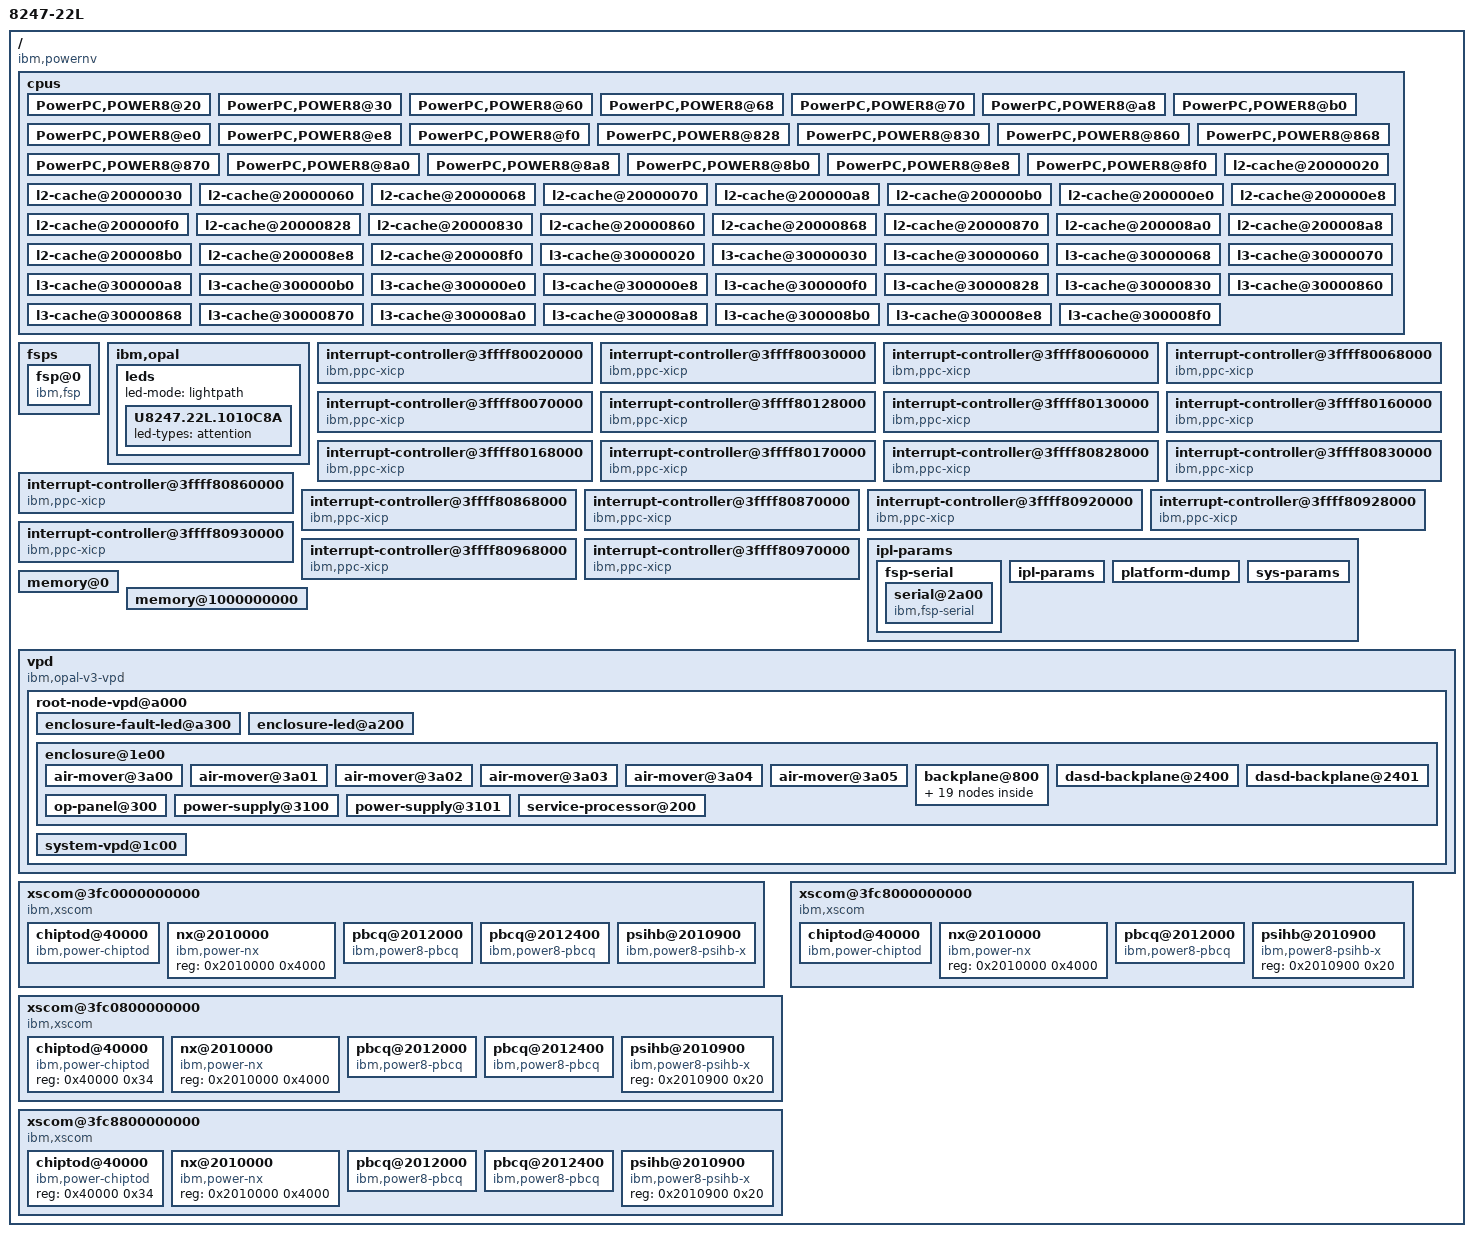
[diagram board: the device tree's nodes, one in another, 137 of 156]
/dts-v1/;

/memreserve/	0x0000001ffd586000 0x0000000000137000;
/memreserve/	0x0000001ffd6bd000 0x0000000000043000;
/memreserve/	0x0000001ffd700000 0x0000000000100000;

/ {
	phandle = <0x1>;
	#address-cells = <0x2>;
	#size-cells = <0x2>;
	lid-type = "phyp";
	compatible = "ibm,powernv", "ibm,firenze";
	nest-frequency = <0x0 0x77359400>;
	vendor = "IBM";
	ibm,io-base-loc-code = "U78CB.001.WZS00AL-P1";
	ibm,vpd-lx-info = <0x0 0x31000401 0x300042>;
	model = "8247-22L";
	system-id = "1010C8A";
	system-brand = "S0";
	model-name = "IBM Power System S822L";
	ibm,hbrt-mini-fdt = <0xcafebeef 0x1000 0xfad5bb>;
	reserved-ranges = <0x1f 0xfd700000 0x0 0x100000 0x1f 0xfd6bd000 0x0 0x43000 0x1f 0xfd586000 0x0 0x137000>;
	reserved-names = "ibm,hbrt-vpd-image", "ibm,hbrt-target-image", "ibm,hbrt-code-image";
	ibm,enabled-idle-states = "nap", "fast-sleep", "rvwinkle";

	cpus {
		phandle = <0x2a>;
		#address-cells = <0x1>;
		#size-cells = <0x0>;

		PowerPC,POWER8@20 {
			phandle = <0x2b>;
			device_type = "cpu";
			status = "okay";
			reg = <0x20>;
			cpu-version = <0x4b0201>;
			64-bit;
			32-64-bridge;
			graphics;
			general-purpose;
			ibm,processor-segment-sizes = <0x1c 0x28 0xffffffff 0xffffffff>;
			ibm,processor-page-sizes = <0xc 0x10 0x18 0x22>;
			ibm,segment-page-sizes = <0xc 0x0 0x3 0xc 0x0 0x10 0x7 0x18 0x38 0x10 0x110 0x2 0x10 0x1 0x18 0x8 0x18 0x100 0x1 0x18 0x0 0x22 0x120 0x1 0x22 0x3>;
			ibm,pa-features = [18 00 f6 3f c7 c0 80 d0 80 00 00 00 00 00 00 00 00 00 80 00 80 00 80 00 80 00];
			ibm,slb-size = <0x20>;
			ibm,vmx = <0x2>;
			ibm,dfp = <0x2>;
			ibm,purr = <0x1>;
			ibm,spurr = <0x1>;
			clock-frequency = <0xcc255a40>;
			ibm,extended-clock-frequency = <0x0 0xcc255a40>;
			timebase-frequency = <0x1e848000>;
			ibm,extended-timebase-frequency = <0x0 0x1e848000>;
			reservation-granule-size = <0x80>;
			d-tlb-size = <0x800>;
			i-tlb-size = <0x0>;
			tlb-size = <0x800>;
			d-tlb-sets = <0x4>;
			i-tlb-sets = <0x0>;
			tlb-sets = <0x4>;
			d-cache-block-size = <0x80>;
			i-cache-block-size = <0x80>;
			d-cache-size = <0x10000>;
			i-cache-size = <0x8000>;
			i-cache-sets = <0x4>;
			d-cache-sets = <0x8>;
			performance-monitor = <0x0 0x1>;
			l2-cache = <0x2c>;
			ibm,pir = <0x20>;
			ibm,chip-id = <0x0>;
			ibm,ppc-interrupt-server#s = <0x20 0x21 0x22 0x23 0x24 0x25 0x26 0x27>;
		};

		PowerPC,POWER8@30 {
			phandle = <0x2f>;
			device_type = "cpu";
			status = "okay";
			reg = <0x30>;
			cpu-version = <0x4b0201>;
			64-bit;
			32-64-bridge;
			graphics;
			general-purpose;
			ibm,processor-segment-sizes = <0x1c 0x28 0xffffffff 0xffffffff>;
			ibm,processor-page-sizes = <0xc 0x10 0x18 0x22>;
			ibm,segment-page-sizes = <0xc 0x0 0x3 0xc 0x0 0x10 0x7 0x18 0x38 0x10 0x110 0x2 0x10 0x1 0x18 0x8 0x18 0x100 0x1 0x18 0x0 0x22 0x120 0x1 0x22 0x3>;
			ibm,pa-features = [18 00 f6 3f c7 c0 80 d0 80 00 00 00 00 00 00 00 00 00 80 00 80 00 80 00 80 00];
			ibm,slb-size = <0x20>;
			ibm,vmx = <0x2>;
			ibm,dfp = <0x2>;
			ibm,purr = <0x1>;
			ibm,spurr = <0x1>;
			clock-frequency = <0xcc255a40>;
			ibm,extended-clock-frequency = <0x0 0xcc255a40>;
			timebase-frequency = <0x1e848000>;
			ibm,extended-timebase-frequency = <0x0 0x1e848000>;
			reservation-granule-size = <0x80>;
			d-tlb-size = <0x800>;
			i-tlb-size = <0x0>;
			tlb-size = <0x800>;
			d-tlb-sets = <0x4>;
			i-tlb-sets = <0x0>;
			tlb-sets = <0x4>;
			d-cache-block-size = <0x80>;
			i-cache-block-size = <0x80>;
			d-cache-size = <0x10000>;
			i-cache-size = <0x8000>;
			i-cache-sets = <0x4>;
			d-cache-sets = <0x8>;
			performance-monitor = <0x0 0x1>;
			l2-cache = <0x30>;
			ibm,pir = <0x30>;
			ibm,chip-id = <0x0>;
			ibm,ppc-interrupt-server#s = <0x30 0x31 0x32 0x33 0x34 0x35 0x36 0x37>;
		};

		PowerPC,POWER8@60 {
			phandle = <0x33>;
			device_type = "cpu";
			status = "okay";
			reg = <0x60>;
			cpu-version = <0x4b0201>;
			64-bit;
			32-64-bridge;
			graphics;
			general-purpose;
			ibm,processor-segment-sizes = <0x1c 0x28 0xffffffff 0xffffffff>;
			ibm,processor-page-sizes = <0xc 0x10 0x18 0x22>;
			ibm,segment-page-sizes = <0xc 0x0 0x3 0xc 0x0 0x10 0x7 0x18 0x38 0x10 0x110 0x2 0x10 0x1 0x18 0x8 0x18 0x100 0x1 0x18 0x0 0x22 0x120 0x1 0x22 0x3>;
			ibm,pa-features = [18 00 f6 3f c7 c0 80 d0 80 00 00 00 00 00 00 00 00 00 80 00 80 00 80 00 80 00];
			ibm,slb-size = <0x20>;
			ibm,vmx = <0x2>;
			ibm,dfp = <0x2>;
			ibm,purr = <0x1>;
			ibm,spurr = <0x1>;
			clock-frequency = <0xcc255a40>;
			ibm,extended-clock-frequency = <0x0 0xcc255a40>;
			timebase-frequency = <0x1e848000>;
			ibm,extended-timebase-frequency = <0x0 0x1e848000>;
			reservation-granule-size = <0x80>;
			d-tlb-size = <0x800>;
			i-tlb-size = <0x0>;
			tlb-size = <0x800>;
			d-tlb-sets = <0x4>;
			i-tlb-sets = <0x0>;
			tlb-sets = <0x4>;
			d-cache-block-size = <0x80>;
			i-cache-block-size = <0x80>;
			d-cache-size = <0x10000>;
			i-cache-size = <0x8000>;
			i-cache-sets = <0x4>;
			d-cache-sets = <0x8>;
			performance-monitor = <0x0 0x1>;
			l2-cache = <0x34>;
			ibm,pir = <0x60>;
			ibm,chip-id = <0x0>;
			ibm,ppc-interrupt-server#s = <0x60 0x61 0x62 0x63 0x64 0x65 0x66 0x67>;
		};

		PowerPC,POWER8@68 {
			phandle = <0x37>;
			device_type = "cpu";
			status = "okay";
			reg = <0x68>;
			cpu-version = <0x4b0201>;
			64-bit;
			32-64-bridge;
			graphics;
			general-purpose;
			ibm,processor-segment-sizes = <0x1c 0x28 0xffffffff 0xffffffff>;
			ibm,processor-page-sizes = <0xc 0x10 0x18 0x22>;
			ibm,segment-page-sizes = <0xc 0x0 0x3 0xc 0x0 0x10 0x7 0x18 0x38 0x10 0x110 0x2 0x10 0x1 0x18 0x8 0x18 0x100 0x1 0x18 0x0 0x22 0x120 0x1 0x22 0x3>;
			ibm,pa-features = [18 00 f6 3f c7 c0 80 d0 80 00 00 00 00 00 00 00 00 00 80 00 80 00 80 00 80 00];
			ibm,slb-size = <0x20>;
			ibm,vmx = <0x2>;
			ibm,dfp = <0x2>;
			ibm,purr = <0x1>;
			ibm,spurr = <0x1>;
			clock-frequency = <0xcc255a40>;
			ibm,extended-clock-frequency = <0x0 0xcc255a40>;
			timebase-frequency = <0x1e848000>;
			ibm,extended-timebase-frequency = <0x0 0x1e848000>;
			reservation-granule-size = <0x80>;
			d-tlb-size = <0x800>;
			i-tlb-size = <0x0>;
			tlb-size = <0x800>;
			d-tlb-sets = <0x4>;
			i-tlb-sets = <0x0>;
			tlb-sets = <0x4>;
			d-cache-block-size = <0x80>;
			i-cache-block-size = <0x80>;
			d-cache-size = <0x10000>;
			i-cache-size = <0x8000>;
			i-cache-sets = <0x4>;
			d-cache-sets = <0x8>;
			performance-monitor = <0x0 0x1>;
			l2-cache = <0x38>;
			ibm,pir = <0x68>;
			ibm,chip-id = <0x0>;
			ibm,ppc-interrupt-server#s = <0x68 0x69 0x6a 0x6b 0x6c 0x6d 0x6e 0x6f>;
		};

		PowerPC,POWER8@70 {
			phandle = <0x3b>;
			device_type = "cpu";
			status = "okay";
			reg = <0x70>;
			cpu-version = <0x4b0201>;
			64-bit;
			32-64-bridge;
			graphics;
			general-purpose;
			ibm,processor-segment-sizes = <0x1c 0x28 0xffffffff 0xffffffff>;
			ibm,processor-page-sizes = <0xc 0x10 0x18 0x22>;
			ibm,segment-page-sizes = <0xc 0x0 0x3 0xc 0x0 0x10 0x7 0x18 0x38 0x10 0x110 0x2 0x10 0x1 0x18 0x8 0x18 0x100 0x1 0x18 0x0 0x22 0x120 0x1 0x22 0x3>;
			ibm,pa-features = [18 00 f6 3f c7 c0 80 d0 80 00 00 00 00 00 00 00 00 00 80 00 80 00 80 00 80 00];
			ibm,slb-size = <0x20>;
			ibm,vmx = <0x2>;
			ibm,dfp = <0x2>;
			ibm,purr = <0x1>;
			ibm,spurr = <0x1>;
			clock-frequency = <0xcc255a40>;
			ibm,extended-clock-frequency = <0x0 0xcc255a40>;
			timebase-frequency = <0x1e848000>;
			ibm,extended-timebase-frequency = <0x0 0x1e848000>;
			reservation-granule-size = <0x80>;
			d-tlb-size = <0x800>;
			i-tlb-size = <0x0>;
			tlb-size = <0x800>;
			d-tlb-sets = <0x4>;
			i-tlb-sets = <0x0>;
			tlb-sets = <0x4>;
			d-cache-block-size = <0x80>;
			i-cache-block-size = <0x80>;
			d-cache-size = <0x10000>;
			i-cache-size = <0x8000>;
			i-cache-sets = <0x4>;
			d-cache-sets = <0x8>;
			performance-monitor = <0x0 0x1>;
			l2-cache = <0x3c>;
			ibm,pir = <0x70>;
			ibm,chip-id = <0x0>;
			ibm,ppc-interrupt-server#s = <0x70 0x71 0x72 0x73 0x74 0x75 0x76 0x77>;
		};

		PowerPC,POWER8@a8 {
			phandle = <0x3f>;
			device_type = "cpu";
			status = "okay";
			reg = <0xa8>;
			cpu-version = <0x4b0201>;
			64-bit;
			32-64-bridge;
			graphics;
			general-purpose;
			ibm,processor-segment-sizes = <0x1c 0x28 0xffffffff 0xffffffff>;
			ibm,processor-page-sizes = <0xc 0x10 0x18 0x22>;
			ibm,segment-page-sizes = <0xc 0x0 0x3 0xc 0x0 0x10 0x7 0x18 0x38 0x10 0x110 0x2 0x10 0x1 0x18 0x8 0x18 0x100 0x1 0x18 0x0 0x22 0x120 0x1 0x22 0x3>;
			ibm,pa-features = [18 00 f6 3f c7 c0 80 d0 80 00 00 00 00 00 00 00 00 00 80 00 80 00 80 00 80 00];
			ibm,slb-size = <0x20>;
			ibm,vmx = <0x2>;
			ibm,dfp = <0x2>;
			ibm,purr = <0x1>;
			ibm,spurr = <0x1>;
			clock-frequency = <0xcc255a40>;
			ibm,extended-clock-frequency = <0x0 0xcc255a40>;
			timebase-frequency = <0x1e848000>;
			ibm,extended-timebase-frequency = <0x0 0x1e848000>;
			reservation-granule-size = <0x80>;
			d-tlb-size = <0x800>;
			i-tlb-size = <0x0>;
			tlb-size = <0x800>;
			d-tlb-sets = <0x4>;
			i-tlb-sets = <0x0>;
			tlb-sets = <0x4>;
			d-cache-block-size = <0x80>;
			i-cache-block-size = <0x80>;
			d-cache-size = <0x10000>;
			i-cache-size = <0x8000>;
			i-cache-sets = <0x4>;
			d-cache-sets = <0x8>;
			performance-monitor = <0x0 0x1>;
			l2-cache = <0x40>;
			ibm,pir = <0xa8>;
			ibm,chip-id = <0x1>;
			ibm,ppc-interrupt-server#s = <0xa8 0xa9 0xaa 0xab 0xac 0xad 0xae 0xaf>;
		};

		PowerPC,POWER8@b0 {
			phandle = <0x43>;
			device_type = "cpu";
			status = "okay";
			reg = <0xb0>;
			cpu-version = <0x4b0201>;
			64-bit;
			32-64-bridge;
			graphics;
			general-purpose;
			ibm,processor-segment-sizes = <0x1c 0x28 0xffffffff 0xffffffff>;
			ibm,processor-page-sizes = <0xc 0x10 0x18 0x22>;
			ibm,segment-page-sizes = <0xc 0x0 0x3 0xc 0x0 0x10 0x7 0x18 0x38 0x10 0x110 0x2 0x10 0x1 0x18 0x8 0x18 0x100 0x1 0x18 0x0 0x22 0x120 0x1 0x22 0x3>;
			ibm,pa-features = [18 00 f6 3f c7 c0 80 d0 80 00 00 00 00 00 00 00 00 00 80 00 80 00 80 00 80 00];
			ibm,slb-size = <0x20>;
			ibm,vmx = <0x2>;
			ibm,dfp = <0x2>;
			ibm,purr = <0x1>;
			ibm,spurr = <0x1>;
			clock-frequency = <0xcc255a40>;
			ibm,extended-clock-frequency = <0x0 0xcc255a40>;
			timebase-frequency = <0x1e848000>;
			ibm,extended-timebase-frequency = <0x0 0x1e848000>;
			reservation-granule-size = <0x80>;
			d-tlb-size = <0x800>;
			i-tlb-size = <0x0>;
			tlb-size = <0x800>;
			d-tlb-sets = <0x4>;
			i-tlb-sets = <0x0>;
			tlb-sets = <0x4>;
			d-cache-block-size = <0x80>;
			i-cache-block-size = <0x80>;
			d-cache-size = <0x10000>;
			i-cache-size = <0x8000>;
			i-cache-sets = <0x4>;
			d-cache-sets = <0x8>;
			performance-monitor = <0x0 0x1>;
			l2-cache = <0x44>;
			ibm,pir = <0xb0>;
			ibm,chip-id = <0x1>;
			ibm,ppc-interrupt-server#s = <0xb0 0xb1 0xb2 0xb3 0xb4 0xb5 0xb6 0xb7>;
		};

		PowerPC,POWER8@e0 {
			phandle = <0x47>;
			device_type = "cpu";
			status = "okay";
			reg = <0xe0>;
			cpu-version = <0x4b0201>;
			64-bit;
			32-64-bridge;
			graphics;
			general-purpose;
			ibm,processor-segment-sizes = <0x1c 0x28 0xffffffff 0xffffffff>;
			ibm,processor-page-sizes = <0xc 0x10 0x18 0x22>;
			ibm,segment-page-sizes = <0xc 0x0 0x3 0xc 0x0 0x10 0x7 0x18 0x38 0x10 0x110 0x2 0x10 0x1 0x18 0x8 0x18 0x100 0x1 0x18 0x0 0x22 0x120 0x1 0x22 0x3>;
			ibm,pa-features = [18 00 f6 3f c7 c0 80 d0 80 00 00 00 00 00 00 00 00 00 80 00 80 00 80 00 80 00];
			ibm,slb-size = <0x20>;
			ibm,vmx = <0x2>;
			ibm,dfp = <0x2>;
			ibm,purr = <0x1>;
			ibm,spurr = <0x1>;
			clock-frequency = <0xcc255a40>;
			ibm,extended-clock-frequency = <0x0 0xcc255a40>;
			timebase-frequency = <0x1e848000>;
			ibm,extended-timebase-frequency = <0x0 0x1e848000>;
			reservation-granule-size = <0x80>;
			d-tlb-size = <0x800>;
			i-tlb-size = <0x0>;
			tlb-size = <0x800>;
			d-tlb-sets = <0x4>;
			i-tlb-sets = <0x0>;
			tlb-sets = <0x4>;
			d-cache-block-size = <0x80>;
			i-cache-block-size = <0x80>;
			d-cache-size = <0x10000>;
			i-cache-size = <0x8000>;
			i-cache-sets = <0x4>;
			d-cache-sets = <0x8>;
			performance-monitor = <0x0 0x1>;
			l2-cache = <0x48>;
			ibm,pir = <0xe0>;
			ibm,chip-id = <0x1>;
			ibm,ppc-interrupt-server#s = <0xe0 0xe1 0xe2 0xe3 0xe4 0xe5 0xe6 0xe7>;
		};

		PowerPC,POWER8@e8 {
			phandle = <0x4b>;
			device_type = "cpu";
			status = "okay";
			reg = <0xe8>;
			cpu-version = <0x4b0201>;
			64-bit;
			32-64-bridge;
			graphics;
			general-purpose;
			ibm,processor-segment-sizes = <0x1c 0x28 0xffffffff 0xffffffff>;
			ibm,processor-page-sizes = <0xc 0x10 0x18 0x22>;
			ibm,segment-page-sizes = <0xc 0x0 0x3 0xc 0x0 0x10 0x7 0x18 0x38 0x10 0x110 0x2 0x10 0x1 0x18 0x8 0x18 0x100 0x1 0x18 0x0 0x22 0x120 0x1 0x22 0x3>;
			ibm,pa-features = [18 00 f6 3f c7 c0 80 d0 80 00 00 00 00 00 00 00 00 00 80 00 80 00 80 00 80 00];
			ibm,slb-size = <0x20>;
			ibm,vmx = <0x2>;
			ibm,dfp = <0x2>;
			ibm,purr = <0x1>;
			ibm,spurr = <0x1>;
			clock-frequency = <0xcc255a40>;
			ibm,extended-clock-frequency = <0x0 0xcc255a40>;
			timebase-frequency = <0x1e848000>;
			ibm,extended-timebase-frequency = <0x0 0x1e848000>;
			reservation-granule-size = <0x80>;
			d-tlb-size = <0x800>;
			i-tlb-size = <0x0>;
			tlb-size = <0x800>;
			d-tlb-sets = <0x4>;
			i-tlb-sets = <0x0>;
			tlb-sets = <0x4>;
			d-cache-block-size = <0x80>;
			i-cache-block-size = <0x80>;
			d-cache-size = <0x10000>;
			i-cache-size = <0x8000>;
			i-cache-sets = <0x4>;
			d-cache-sets = <0x8>;
			performance-monitor = <0x0 0x1>;
			l2-cache = <0x4c>;
			ibm,pir = <0xe8>;
			ibm,chip-id = <0x1>;
			ibm,ppc-interrupt-server#s = <0xe8 0xe9 0xea 0xeb 0xec 0xed 0xee 0xef>;
		};

		PowerPC,POWER8@f0 {
			phandle = <0x4f>;
			device_type = "cpu";
			status = "okay";
			reg = <0xf0>;
			cpu-version = <0x4b0201>;
			64-bit;
			32-64-bridge;
			graphics;
			general-purpose;
			ibm,processor-segment-sizes = <0x1c 0x28 0xffffffff 0xffffffff>;
			ibm,processor-page-sizes = <0xc 0x10 0x18 0x22>;
			ibm,segment-page-sizes = <0xc 0x0 0x3 0xc 0x0 0x10 0x7 0x18 0x38 0x10 0x110 0x2 0x10 0x1 0x18 0x8 0x18 0x100 0x1 0x18 0x0 0x22 0x120 0x1 0x22 0x3>;
			ibm,pa-features = [18 00 f6 3f c7 c0 80 d0 80 00 00 00 00 00 00 00 00 00 80 00 80 00 80 00 80 00];
			ibm,slb-size = <0x20>;
			ibm,vmx = <0x2>;
			ibm,dfp = <0x2>;
			ibm,purr = <0x1>;
			ibm,spurr = <0x1>;
			clock-frequency = <0xcc255a40>;
			ibm,extended-clock-frequency = <0x0 0xcc255a40>;
			timebase-frequency = <0x1e848000>;
			ibm,extended-timebase-frequency = <0x0 0x1e848000>;
			reservation-granule-size = <0x80>;
			d-tlb-size = <0x800>;
			i-tlb-size = <0x0>;
			tlb-size = <0x800>;
			d-tlb-sets = <0x4>;
			i-tlb-sets = <0x0>;
			tlb-sets = <0x4>;
			d-cache-block-size = <0x80>;
			i-cache-block-size = <0x80>;
			d-cache-size = <0x10000>;
			i-cache-size = <0x8000>;
			i-cache-sets = <0x4>;
			d-cache-sets = <0x8>;
			performance-monitor = <0x0 0x1>;
			l2-cache = <0x50>;
			ibm,pir = <0xf0>;
			ibm,chip-id = <0x1>;
			ibm,ppc-interrupt-server#s = <0xf0 0xf1 0xf2 0xf3 0xf4 0xf5 0xf6 0xf7>;
		};

		PowerPC,POWER8@828 {
			phandle = <0x53>;
			device_type = "cpu";
			status = "okay";
			reg = <0x828>;
			cpu-version = <0x4b0201>;
			64-bit;
			32-64-bridge;
			graphics;
			general-purpose;
			ibm,processor-segment-sizes = <0x1c 0x28 0xffffffff 0xffffffff>;
			ibm,processor-page-sizes = <0xc 0x10 0x18 0x22>;
			ibm,segment-page-sizes = <0xc 0x0 0x3 0xc 0x0 0x10 0x7 0x18 0x38 0x10 0x110 0x2 0x10 0x1 0x18 0x8 0x18 0x100 0x1 0x18 0x0 0x22 0x120 0x1 0x22 0x3>;
			ibm,pa-features = [18 00 f6 3f c7 c0 80 d0 80 00 00 00 00 00 00 00 00 00 80 00 80 00 80 00 80 00];
			ibm,slb-size = <0x20>;
			ibm,vmx = <0x2>;
			ibm,dfp = <0x2>;
			ibm,purr = <0x1>;
			ibm,spurr = <0x1>;
			clock-frequency = <0xcc255a40>;
			ibm,extended-clock-frequency = <0x0 0xcc255a40>;
			timebase-frequency = <0x1e848000>;
			ibm,extended-timebase-frequency = <0x0 0x1e848000>;
			reservation-granule-size = <0x80>;
			d-tlb-size = <0x800>;
			i-tlb-size = <0x0>;
			tlb-size = <0x800>;
			d-tlb-sets = <0x4>;
			i-tlb-sets = <0x0>;
			tlb-sets = <0x4>;
			d-cache-block-size = <0x80>;
			i-cache-block-size = <0x80>;
			d-cache-size = <0x10000>;
			i-cache-size = <0x8000>;
			i-cache-sets = <0x4>;
			d-cache-sets = <0x8>;
			performance-monitor = <0x0 0x1>;
			l2-cache = <0x54>;
			ibm,pir = <0x828>;
			ibm,chip-id = <0x10>;
			ibm,ppc-interrupt-server#s = <0x828 0x829 0x82a 0x82b 0x82c 0x82d 0x82e 0x82f>;
		};

		PowerPC,POWER8@830 {
			phandle = <0x57>;
			device_type = "cpu";
			status = "okay";
			reg = <0x830>;
			cpu-version = <0x4b0201>;
			64-bit;
			32-64-bridge;
			graphics;
			general-purpose;
			ibm,processor-segment-sizes = <0x1c 0x28 0xffffffff 0xffffffff>;
			ibm,processor-page-sizes = <0xc 0x10 0x18 0x22>;
			ibm,segment-page-sizes = <0xc 0x0 0x3 0xc 0x0 0x10 0x7 0x18 0x38 0x10 0x110 0x2 0x10 0x1 0x18 0x8 0x18 0x100 0x1 0x18 0x0 0x22 0x120 0x1 0x22 0x3>;
			ibm,pa-features = [18 00 f6 3f c7 c0 80 d0 80 00 00 00 00 00 00 00 00 00 80 00 80 00 80 00 80 00];
			ibm,slb-size = <0x20>;
			ibm,vmx = <0x2>;
			ibm,dfp = <0x2>;
			ibm,purr = <0x1>;
			ibm,spurr = <0x1>;
			clock-frequency = <0xcc255a40>;
			ibm,extended-clock-frequency = <0x0 0xcc255a40>;
			timebase-frequency = <0x1e848000>;
			ibm,extended-timebase-frequency = <0x0 0x1e848000>;
			reservation-granule-size = <0x80>;
			d-tlb-size = <0x800>;
			i-tlb-size = <0x0>;
			tlb-size = <0x800>;
			d-tlb-sets = <0x4>;
			i-tlb-sets = <0x0>;
			tlb-sets = <0x4>;
			d-cache-block-size = <0x80>;
			i-cache-block-size = <0x80>;
			d-cache-size = <0x10000>;
			i-cache-size = <0x8000>;
			i-cache-sets = <0x4>;
			d-cache-sets = <0x8>;
			performance-monitor = <0x0 0x1>;
			l2-cache = <0x58>;
			ibm,pir = <0x830>;
			ibm,chip-id = <0x10>;
			ibm,ppc-interrupt-server#s = <0x830 0x831 0x832 0x833 0x834 0x835 0x836 0x837>;
		};

		PowerPC,POWER8@860 {
			phandle = <0x5b>;
			device_type = "cpu";
			status = "okay";
			reg = <0x860>;
			cpu-version = <0x4b0201>;
			64-bit;
			32-64-bridge;
			graphics;
			general-purpose;
			ibm,processor-segment-sizes = <0x1c 0x28 0xffffffff 0xffffffff>;
			ibm,processor-page-sizes = <0xc 0x10 0x18 0x22>;
			ibm,segment-page-sizes = <0xc 0x0 0x3 0xc 0x0 0x10 0x7 0x18 0x38 0x10 0x110 0x2 0x10 0x1 0x18 0x8 0x18 0x100 0x1 0x18 0x0 0x22 0x120 0x1 0x22 0x3>;
			ibm,pa-features = [18 00 f6 3f c7 c0 80 d0 80 00 00 00 00 00 00 00 00 00 80 00 80 00 80 00 80 00];
			ibm,slb-size = <0x20>;
			ibm,vmx = <0x2>;
			ibm,dfp = <0x2>;
			ibm,purr = <0x1>;
			ibm,spurr = <0x1>;
			clock-frequency = <0xcc255a40>;
			ibm,extended-clock-frequency = <0x0 0xcc255a40>;
			timebase-frequency = <0x1e848000>;
			ibm,extended-timebase-frequency = <0x0 0x1e848000>;
			reservation-granule-size = <0x80>;
			d-tlb-size = <0x800>;
			i-tlb-size = <0x0>;
			tlb-size = <0x800>;
			d-tlb-sets = <0x4>;
			i-tlb-sets = <0x0>;
			tlb-sets = <0x4>;
			d-cache-block-size = <0x80>;
			i-cache-block-size = <0x80>;
			d-cache-size = <0x10000>;
			i-cache-size = <0x8000>;
			i-cache-sets = <0x4>;
			d-cache-sets = <0x8>;
			performance-monitor = <0x0 0x1>;
			l2-cache = <0x5c>;
			ibm,pir = <0x860>;
			ibm,chip-id = <0x10>;
			ibm,ppc-interrupt-server#s = <0x860 0x861 0x862 0x863 0x864 0x865 0x866 0x867>;
		};

		PowerPC,POWER8@868 {
			phandle = <0x5f>;
			device_type = "cpu";
			status = "okay";
			reg = <0x868>;
			cpu-version = <0x4b0201>;
			64-bit;
			32-64-bridge;
			graphics;
			general-purpose;
			ibm,processor-segment-sizes = <0x1c 0x28 0xffffffff 0xffffffff>;
			ibm,processor-page-sizes = <0xc 0x10 0x18 0x22>;
			ibm,segment-page-sizes = <0xc 0x0 0x3 0xc 0x0 0x10 0x7 0x18 0x38 0x10 0x110 0x2 0x10 0x1 0x18 0x8 0x18 0x100 0x1 0x18 0x0 0x22 0x120 0x1 0x22 0x3>;
			ibm,pa-features = [18 00 f6 3f c7 c0 80 d0 80 00 00 00 00 00 00 00 00 00 80 00 80 00 80 00 80 00];
			ibm,slb-size = <0x20>;
			ibm,vmx = <0x2>;
			ibm,dfp = <0x2>;
			ibm,purr = <0x1>;
			ibm,spurr = <0x1>;
			clock-frequency = <0xcc255a40>;
			ibm,extended-clock-frequency = <0x0 0xcc255a40>;
			timebase-frequency = <0x1e848000>;
			ibm,extended-timebase-frequency = <0x0 0x1e848000>;
			reservation-granule-size = <0x80>;
			d-tlb-size = <0x800>;
			i-tlb-size = <0x0>;
			tlb-size = <0x800>;
			d-tlb-sets = <0x4>;
			i-tlb-sets = <0x0>;
			tlb-sets = <0x4>;
			d-cache-block-size = <0x80>;
			i-cache-block-size = <0x80>;
			d-cache-size = <0x10000>;
			i-cache-size = <0x8000>;
			i-cache-sets = <0x4>;
			d-cache-sets = <0x8>;
			performance-monitor = <0x0 0x1>;
			l2-cache = <0x60>;
			ibm,pir = <0x868>;
			ibm,chip-id = <0x10>;
			ibm,ppc-interrupt-server#s = <0x868 0x869 0x86a 0x86b 0x86c 0x86d 0x86e 0x86f>;
		};

		PowerPC,POWER8@870 {
			phandle = <0x63>;
			device_type = "cpu";
			status = "okay";
			reg = <0x870>;
			cpu-version = <0x4b0201>;
			64-bit;
			32-64-bridge;
			graphics;
			general-purpose;
			ibm,processor-segment-sizes = <0x1c 0x28 0xffffffff 0xffffffff>;
			ibm,processor-page-sizes = <0xc 0x10 0x18 0x22>;
			ibm,segment-page-sizes = <0xc 0x0 0x3 0xc 0x0 0x10 0x7 0x18 0x38 0x10 0x110 0x2 0x10 0x1 0x18 0x8 0x18 0x100 0x1 0x18 0x0 0x22 0x120 0x1 0x22 0x3>;
			ibm,pa-features = [18 00 f6 3f c7 c0 80 d0 80 00 00 00 00 00 00 00 00 00 80 00 80 00 80 00 80 00];
			ibm,slb-size = <0x20>;
			ibm,vmx = <0x2>;
			ibm,dfp = <0x2>;
			ibm,purr = <0x1>;
			ibm,spurr = <0x1>;
			clock-frequency = <0xcc255a40>;
			ibm,extended-clock-frequency = <0x0 0xcc255a40>;
			timebase-frequency = <0x1e848000>;
			ibm,extended-timebase-frequency = <0x0 0x1e848000>;
			reservation-granule-size = <0x80>;
			d-tlb-size = <0x800>;
			i-tlb-size = <0x0>;
			tlb-size = <0x800>;
			d-tlb-sets = <0x4>;
			i-tlb-sets = <0x0>;
			tlb-sets = <0x4>;
			d-cache-block-size = <0x80>;
			i-cache-block-size = <0x80>;
			d-cache-size = <0x10000>;
			i-cache-size = <0x8000>;
			i-cache-sets = <0x4>;
			d-cache-sets = <0x8>;
			performance-monitor = <0x0 0x1>;
			l2-cache = <0x64>;
			ibm,pir = <0x870>;
			ibm,chip-id = <0x10>;
			ibm,ppc-interrupt-server#s = <0x870 0x871 0x872 0x873 0x874 0x875 0x876 0x877>;
		};

		PowerPC,POWER8@8a0 {
			phandle = <0x67>;
			device_type = "cpu";
			status = "okay";
			reg = <0x8a0>;
			cpu-version = <0x4b0201>;
			64-bit;
			32-64-bridge;
			graphics;
			general-purpose;
			ibm,processor-segment-sizes = <0x1c 0x28 0xffffffff 0xffffffff>;
			ibm,processor-page-sizes = <0xc 0x10 0x18 0x22>;
			ibm,segment-page-sizes = <0xc 0x0 0x3 0xc 0x0 0x10 0x7 0x18 0x38 0x10 0x110 0x2 0x10 0x1 0x18 0x8 0x18 0x100 0x1 0x18 0x0 0x22 0x120 0x1 0x22 0x3>;
			ibm,pa-features = [18 00 f6 3f c7 c0 80 d0 80 00 00 00 00 00 00 00 00 00 80 00 80 00 80 00 80 00];
			ibm,slb-size = <0x20>;
			ibm,vmx = <0x2>;
			ibm,dfp = <0x2>;
			ibm,purr = <0x1>;
			ibm,spurr = <0x1>;
			clock-frequency = <0xcc255a40>;
			ibm,extended-clock-frequency = <0x0 0xcc255a40>;
			timebase-frequency = <0x1e848000>;
			ibm,extended-timebase-frequency = <0x0 0x1e848000>;
			reservation-granule-size = <0x80>;
			d-tlb-size = <0x800>;
			i-tlb-size = <0x0>;
			tlb-size = <0x800>;
			d-tlb-sets = <0x4>;
			i-tlb-sets = <0x0>;
			tlb-sets = <0x4>;
			d-cache-block-size = <0x80>;
			i-cache-block-size = <0x80>;
			d-cache-size = <0x10000>;
			i-cache-size = <0x8000>;
			i-cache-sets = <0x4>;
			d-cache-sets = <0x8>;
			performance-monitor = <0x0 0x1>;
			l2-cache = <0x68>;
			ibm,pir = <0x8a0>;
			ibm,chip-id = <0x11>;
			ibm,ppc-interrupt-server#s = <0x8a0 0x8a1 0x8a2 0x8a3 0x8a4 0x8a5 0x8a6 0x8a7>;
		};

		PowerPC,POWER8@8a8 {
			phandle = <0x6b>;
			device_type = "cpu";
			status = "okay";
			reg = <0x8a8>;
			cpu-version = <0x4b0201>;
			64-bit;
			32-64-bridge;
			graphics;
			general-purpose;
			ibm,processor-segment-sizes = <0x1c 0x28 0xffffffff 0xffffffff>;
			ibm,processor-page-sizes = <0xc 0x10 0x18 0x22>;
			ibm,segment-page-sizes = <0xc 0x0 0x3 0xc 0x0 0x10 0x7 0x18 0x38 0x10 0x110 0x2 0x10 0x1 0x18 0x8 0x18 0x100 0x1 0x18 0x0 0x22 0x120 0x1 0x22 0x3>;
			ibm,pa-features = [18 00 f6 3f c7 c0 80 d0 80 00 00 00 00 00 00 00 00 00 80 00 80 00 80 00 80 00];
			ibm,slb-size = <0x20>;
			ibm,vmx = <0x2>;
			ibm,dfp = <0x2>;
			ibm,purr = <0x1>;
			ibm,spurr = <0x1>;
			clock-frequency = <0xcc255a40>;
			ibm,extended-clock-frequency = <0x0 0xcc255a40>;
			timebase-frequency = <0x1e848000>;
			ibm,extended-timebase-frequency = <0x0 0x1e848000>;
			reservation-granule-size = <0x80>;
			d-tlb-size = <0x800>;
			i-tlb-size = <0x0>;
			tlb-size = <0x800>;
			d-tlb-sets = <0x4>;
			i-tlb-sets = <0x0>;
			tlb-sets = <0x4>;
			d-cache-block-size = <0x80>;
			i-cache-block-size = <0x80>;
			d-cache-size = <0x10000>;
			i-cache-size = <0x8000>;
			i-cache-sets = <0x4>;
			d-cache-sets = <0x8>;
			performance-monitor = <0x0 0x1>;
			l2-cache = <0x6c>;
			ibm,pir = <0x8a8>;
			ibm,chip-id = <0x11>;
			ibm,ppc-interrupt-server#s = <0x8a8 0x8a9 0x8aa 0x8ab 0x8ac 0x8ad 0x8ae 0x8af>;
		};

		PowerPC,POWER8@8b0 {
			phandle = <0x6f>;
			device_type = "cpu";
			status = "okay";
			reg = <0x8b0>;
			cpu-version = <0x4b0201>;
			64-bit;
			32-64-bridge;
			graphics;
			general-purpose;
			ibm,processor-segment-sizes = <0x1c 0x28 0xffffffff 0xffffffff>;
			ibm,processor-page-sizes = <0xc 0x10 0x18 0x22>;
			ibm,segment-page-sizes = <0xc 0x0 0x3 0xc 0x0 0x10 0x7 0x18 0x38 0x10 0x110 0x2 0x10 0x1 0x18 0x8 0x18 0x100 0x1 0x18 0x0 0x22 0x120 0x1 0x22 0x3>;
			ibm,pa-features = [18 00 f6 3f c7 c0 80 d0 80 00 00 00 00 00 00 00 00 00 80 00 80 00 80 00 80 00];
			ibm,slb-size = <0x20>;
			ibm,vmx = <0x2>;
			ibm,dfp = <0x2>;
			ibm,purr = <0x1>;
			ibm,spurr = <0x1>;
			clock-frequency = <0xcc255a40>;
			ibm,extended-clock-frequency = <0x0 0xcc255a40>;
			timebase-frequency = <0x1e848000>;
			ibm,extended-timebase-frequency = <0x0 0x1e848000>;
			reservation-granule-size = <0x80>;
			d-tlb-size = <0x800>;
			i-tlb-size = <0x0>;
			tlb-size = <0x800>;
			d-tlb-sets = <0x4>;
			i-tlb-sets = <0x0>;
			tlb-sets = <0x4>;
			d-cache-block-size = <0x80>;
			i-cache-block-size = <0x80>;
			d-cache-size = <0x10000>;
			i-cache-size = <0x8000>;
			i-cache-sets = <0x4>;
			d-cache-sets = <0x8>;
			performance-monitor = <0x0 0x1>;
			l2-cache = <0x70>;
			ibm,pir = <0x8b0>;
			ibm,chip-id = <0x11>;
			ibm,ppc-interrupt-server#s = <0x8b0 0x8b1 0x8b2 0x8b3 0x8b4 0x8b5 0x8b6 0x8b7>;
		};

		PowerPC,POWER8@8e8 {
			phandle = <0x73>;
			device_type = "cpu";
			status = "okay";
			reg = <0x8e8>;
			cpu-version = <0x4b0201>;
			64-bit;
			32-64-bridge;
			graphics;
			general-purpose;
			ibm,processor-segment-sizes = <0x1c 0x28 0xffffffff 0xffffffff>;
			ibm,processor-page-sizes = <0xc 0x10 0x18 0x22>;
			ibm,segment-page-sizes = <0xc 0x0 0x3 0xc 0x0 0x10 0x7 0x18 0x38 0x10 0x110 0x2 0x10 0x1 0x18 0x8 0x18 0x100 0x1 0x18 0x0 0x22 0x120 0x1 0x22 0x3>;
			ibm,pa-features = [18 00 f6 3f c7 c0 80 d0 80 00 00 00 00 00 00 00 00 00 80 00 80 00 80 00 80 00];
			ibm,slb-size = <0x20>;
			ibm,vmx = <0x2>;
			ibm,dfp = <0x2>;
			ibm,purr = <0x1>;
			ibm,spurr = <0x1>;
			clock-frequency = <0xcc255a40>;
			ibm,extended-clock-frequency = <0x0 0xcc255a40>;
			timebase-frequency = <0x1e848000>;
			ibm,extended-timebase-frequency = <0x0 0x1e848000>;
			reservation-granule-size = <0x80>;
			d-tlb-size = <0x800>;
			i-tlb-size = <0x0>;
			tlb-size = <0x800>;
			d-tlb-sets = <0x4>;
			i-tlb-sets = <0x0>;
			tlb-sets = <0x4>;
			d-cache-block-size = <0x80>;
			i-cache-block-size = <0x80>;
			d-cache-size = <0x10000>;
			i-cache-size = <0x8000>;
			i-cache-sets = <0x4>;
			d-cache-sets = <0x8>;
			performance-monitor = <0x0 0x1>;
			l2-cache = <0x74>;
			ibm,pir = <0x8e8>;
			ibm,chip-id = <0x11>;
			ibm,ppc-interrupt-server#s = <0x8e8 0x8e9 0x8ea 0x8eb 0x8ec 0x8ed 0x8ee 0x8ef>;
		};

		PowerPC,POWER8@8f0 {
			phandle = <0x77>;
			device_type = "cpu";
			status = "okay";
			reg = <0x8f0>;
			cpu-version = <0x4b0201>;
			64-bit;
			32-64-bridge;
			graphics;
			general-purpose;
			ibm,processor-segment-sizes = <0x1c 0x28 0xffffffff 0xffffffff>;
			ibm,processor-page-sizes = <0xc 0x10 0x18 0x22>;
			ibm,segment-page-sizes = <0xc 0x0 0x3 0xc 0x0 0x10 0x7 0x18 0x38 0x10 0x110 0x2 0x10 0x1 0x18 0x8 0x18 0x100 0x1 0x18 0x0 0x22 0x120 0x1 0x22 0x3>;
			ibm,pa-features = [18 00 f6 3f c7 c0 80 d0 80 00 00 00 00 00 00 00 00 00 80 00 80 00 80 00 80 00];
			ibm,slb-size = <0x20>;
			ibm,vmx = <0x2>;
			ibm,dfp = <0x2>;
			ibm,purr = <0x1>;
			ibm,spurr = <0x1>;
			clock-frequency = <0xcc255a40>;
			ibm,extended-clock-frequency = <0x0 0xcc255a40>;
			timebase-frequency = <0x1e848000>;
			ibm,extended-timebase-frequency = <0x0 0x1e848000>;
			reservation-granule-size = <0x80>;
			d-tlb-size = <0x800>;
			i-tlb-size = <0x0>;
			tlb-size = <0x800>;
			d-tlb-sets = <0x4>;
			i-tlb-sets = <0x0>;
			tlb-sets = <0x4>;
			d-cache-block-size = <0x80>;
			i-cache-block-size = <0x80>;
			d-cache-size = <0x10000>;
			i-cache-size = <0x8000>;
			i-cache-sets = <0x4>;
			d-cache-sets = <0x8>;
			performance-monitor = <0x0 0x1>;
			l2-cache = <0x78>;
			ibm,pir = <0x8f0>;
			ibm,chip-id = <0x11>;
			ibm,ppc-interrupt-server#s = <0x8f0 0x8f1 0x8f2 0x8f3 0x8f4 0x8f5 0x8f6 0x8f7>;
		};

		l2-cache@20000020 {
			phandle = <0x2c>;
			device_type = "cache";
			reg = <0x20000020>;
			status = "okay";
			cache-unified;
			d-cache-sets = <0x8>;
			i-cache-sets = <0x8>;
			d-cache-size = <0x80000>;
			i-cache-size = <0x80000>;
			l2-cache = <0x2d>;
		};

		l2-cache@20000030 {
			phandle = <0x30>;
			device_type = "cache";
			reg = <0x20000030>;
			status = "okay";
			cache-unified;
			d-cache-sets = <0x8>;
			i-cache-sets = <0x8>;
			d-cache-size = <0x80000>;
			i-cache-size = <0x80000>;
			l2-cache = <0x31>;
		};

		l2-cache@20000060 {
			phandle = <0x34>;
			device_type = "cache";
			reg = <0x20000060>;
			status = "okay";
			cache-unified;
			d-cache-sets = <0x8>;
			i-cache-sets = <0x8>;
			d-cache-size = <0x80000>;
			i-cache-size = <0x80000>;
			l2-cache = <0x35>;
		};

		l2-cache@20000068 {
			phandle = <0x38>;
			device_type = "cache";
			reg = <0x20000068>;
			status = "okay";
			cache-unified;
			d-cache-sets = <0x8>;
			i-cache-sets = <0x8>;
			d-cache-size = <0x80000>;
			i-cache-size = <0x80000>;
			l2-cache = <0x39>;
		};

		l2-cache@20000070 {
			phandle = <0x3c>;
			device_type = "cache";
			reg = <0x20000070>;
			status = "okay";
			cache-unified;
			d-cache-sets = <0x8>;
			i-cache-sets = <0x8>;
			d-cache-size = <0x80000>;
			i-cache-size = <0x80000>;
			l2-cache = <0x3d>;
		};

		l2-cache@200000a8 {
			phandle = <0x40>;
			device_type = "cache";
			reg = <0x200000a8>;
			status = "okay";
			cache-unified;
			d-cache-sets = <0x8>;
			i-cache-sets = <0x8>;
			d-cache-size = <0x80000>;
			i-cache-size = <0x80000>;
			l2-cache = <0x41>;
		};

		l2-cache@200000b0 {
			phandle = <0x44>;
			device_type = "cache";
			reg = <0x200000b0>;
			status = "okay";
			cache-unified;
			d-cache-sets = <0x8>;
			i-cache-sets = <0x8>;
			d-cache-size = <0x80000>;
			i-cache-size = <0x80000>;
			l2-cache = <0x45>;
		};

		l2-cache@200000e0 {
			phandle = <0x48>;
			device_type = "cache";
			reg = <0x200000e0>;
			status = "okay";
			cache-unified;
			d-cache-sets = <0x8>;
			i-cache-sets = <0x8>;
			d-cache-size = <0x80000>;
			i-cache-size = <0x80000>;
			l2-cache = <0x49>;
		};

		l2-cache@200000e8 {
			phandle = <0x4c>;
			device_type = "cache";
			reg = <0x200000e8>;
			status = "okay";
			cache-unified;
			d-cache-sets = <0x8>;
			i-cache-sets = <0x8>;
			d-cache-size = <0x80000>;
			i-cache-size = <0x80000>;
			l2-cache = <0x4d>;
		};

		l2-cache@200000f0 {
			phandle = <0x50>;
			device_type = "cache";
			reg = <0x200000f0>;
			status = "okay";
			cache-unified;
			d-cache-sets = <0x8>;
			i-cache-sets = <0x8>;
			d-cache-size = <0x80000>;
			i-cache-size = <0x80000>;
			l2-cache = <0x51>;
		};

		l2-cache@20000828 {
			phandle = <0x54>;
			device_type = "cache";
			reg = <0x20000828>;
			status = "okay";
			cache-unified;
			d-cache-sets = <0x8>;
			i-cache-sets = <0x8>;
			d-cache-size = <0x80000>;
			i-cache-size = <0x80000>;
			l2-cache = <0x55>;
		};

		l2-cache@20000830 {
			phandle = <0x58>;
			device_type = "cache";
			reg = <0x20000830>;
			status = "okay";
			cache-unified;
			d-cache-sets = <0x8>;
			i-cache-sets = <0x8>;
			d-cache-size = <0x80000>;
			i-cache-size = <0x80000>;
			l2-cache = <0x59>;
		};

		l2-cache@20000860 {
			phandle = <0x5c>;
			device_type = "cache";
			reg = <0x20000860>;
			status = "okay";
			cache-unified;
			d-cache-sets = <0x8>;
			i-cache-sets = <0x8>;
			d-cache-size = <0x80000>;
			i-cache-size = <0x80000>;
			l2-cache = <0x5d>;
		};

		l2-cache@20000868 {
			phandle = <0x60>;
			device_type = "cache";
			reg = <0x20000868>;
			status = "okay";
			cache-unified;
			d-cache-sets = <0x8>;
			i-cache-sets = <0x8>;
			d-cache-size = <0x80000>;
			i-cache-size = <0x80000>;
			l2-cache = <0x61>;
		};

		l2-cache@20000870 {
			phandle = <0x64>;
			device_type = "cache";
			reg = <0x20000870>;
			status = "okay";
			cache-unified;
			d-cache-sets = <0x8>;
			i-cache-sets = <0x8>;
			d-cache-size = <0x80000>;
			i-cache-size = <0x80000>;
			l2-cache = <0x65>;
		};

		l2-cache@200008a0 {
			phandle = <0x68>;
			device_type = "cache";
			reg = <0x200008a0>;
			status = "okay";
			cache-unified;
			d-cache-sets = <0x8>;
			i-cache-sets = <0x8>;
			d-cache-size = <0x80000>;
			i-cache-size = <0x80000>;
			l2-cache = <0x69>;
		};

		l2-cache@200008a8 {
			phandle = <0x6c>;
			device_type = "cache";
			reg = <0x200008a8>;
			status = "okay";
			cache-unified;
			d-cache-sets = <0x8>;
			i-cache-sets = <0x8>;
			d-cache-size = <0x80000>;
			i-cache-size = <0x80000>;
			l2-cache = <0x6d>;
		};

		l2-cache@200008b0 {
			phandle = <0x70>;
			device_type = "cache";
			reg = <0x200008b0>;
			status = "okay";
			cache-unified;
			d-cache-sets = <0x8>;
			i-cache-sets = <0x8>;
			d-cache-size = <0x80000>;
			i-cache-size = <0x80000>;
			l2-cache = <0x71>;
		};

		l2-cache@200008e8 {
			phandle = <0x74>;
			device_type = "cache";
			reg = <0x200008e8>;
			status = "okay";
			cache-unified;
			d-cache-sets = <0x8>;
			i-cache-sets = <0x8>;
			d-cache-size = <0x80000>;
			i-cache-size = <0x80000>;
			l2-cache = <0x75>;
		};

		l2-cache@200008f0 {
			phandle = <0x78>;
			device_type = "cache";
			reg = <0x200008f0>;
			status = "okay";
			cache-unified;
			d-cache-sets = <0x8>;
			i-cache-sets = <0x8>;
			d-cache-size = <0x80000>;
			i-cache-size = <0x80000>;
			l2-cache = <0x79>;
		};

		l3-cache@30000020 {
			phandle = <0x2d>;
			device_type = "cache";
			reg = <0x30000020>;
			status = "okay";
			cache-unified;
			d-cache-sets = <0x8>;
			i-cache-sets = <0x8>;
			d-cache-size = <0x800000>;
			i-cache-size = <0x800000>;
		};

		l3-cache@30000030 {
			phandle = <0x31>;
			device_type = "cache";
			reg = <0x30000030>;
			status = "okay";
			cache-unified;
			d-cache-sets = <0x8>;
			i-cache-sets = <0x8>;
			d-cache-size = <0x800000>;
			i-cache-size = <0x800000>;
		};

		l3-cache@30000060 {
			phandle = <0x35>;
			device_type = "cache";
			reg = <0x30000060>;
			status = "okay";
			cache-unified;
			d-cache-sets = <0x8>;
			i-cache-sets = <0x8>;
			d-cache-size = <0x800000>;
			i-cache-size = <0x800000>;
		};

		l3-cache@30000068 {
			phandle = <0x39>;
			device_type = "cache";
			reg = <0x30000068>;
			status = "okay";
			cache-unified;
			d-cache-sets = <0x8>;
			i-cache-sets = <0x8>;
			d-cache-size = <0x800000>;
			i-cache-size = <0x800000>;
		};

		l3-cache@30000070 {
			phandle = <0x3d>;
			device_type = "cache";
			reg = <0x30000070>;
			status = "okay";
			cache-unified;
			d-cache-sets = <0x8>;
			i-cache-sets = <0x8>;
			d-cache-size = <0x800000>;
			i-cache-size = <0x800000>;
		};

		l3-cache@300000a8 {
			phandle = <0x41>;
			device_type = "cache";
			reg = <0x300000a8>;
			status = "okay";
			cache-unified;
			d-cache-sets = <0x8>;
			i-cache-sets = <0x8>;
			d-cache-size = <0x800000>;
			i-cache-size = <0x800000>;
		};

		l3-cache@300000b0 {
			phandle = <0x45>;
			device_type = "cache";
			reg = <0x300000b0>;
			status = "okay";
			cache-unified;
			d-cache-sets = <0x8>;
			i-cache-sets = <0x8>;
			d-cache-size = <0x800000>;
			i-cache-size = <0x800000>;
		};

		l3-cache@300000e0 {
			phandle = <0x49>;
			device_type = "cache";
			reg = <0x300000e0>;
			status = "okay";
			cache-unified;
			d-cache-sets = <0x8>;
			i-cache-sets = <0x8>;
			d-cache-size = <0x800000>;
			i-cache-size = <0x800000>;
		};

		l3-cache@300000e8 {
			phandle = <0x4d>;
			device_type = "cache";
			reg = <0x300000e8>;
			status = "okay";
			cache-unified;
			d-cache-sets = <0x8>;
			i-cache-sets = <0x8>;
			d-cache-size = <0x800000>;
			i-cache-size = <0x800000>;
		};

		l3-cache@300000f0 {
			phandle = <0x51>;
			device_type = "cache";
			reg = <0x300000f0>;
			status = "okay";
			cache-unified;
			d-cache-sets = <0x8>;
			i-cache-sets = <0x8>;
			d-cache-size = <0x800000>;
			i-cache-size = <0x800000>;
		};

		l3-cache@30000828 {
			phandle = <0x55>;
			device_type = "cache";
			reg = <0x30000828>;
			status = "okay";
			cache-unified;
			d-cache-sets = <0x8>;
			i-cache-sets = <0x8>;
			d-cache-size = <0x800000>;
			i-cache-size = <0x800000>;
		};

		l3-cache@30000830 {
			phandle = <0x59>;
			device_type = "cache";
			reg = <0x30000830>;
			status = "okay";
			cache-unified;
			d-cache-sets = <0x8>;
			i-cache-sets = <0x8>;
			d-cache-size = <0x800000>;
			i-cache-size = <0x800000>;
		};

		l3-cache@30000860 {
			phandle = <0x5d>;
			device_type = "cache";
			reg = <0x30000860>;
			status = "okay";
			cache-unified;
			d-cache-sets = <0x8>;
			i-cache-sets = <0x8>;
			d-cache-size = <0x800000>;
			i-cache-size = <0x800000>;
		};

		l3-cache@30000868 {
			phandle = <0x61>;
			device_type = "cache";
			reg = <0x30000868>;
			status = "okay";
			cache-unified;
			d-cache-sets = <0x8>;
			i-cache-sets = <0x8>;
			d-cache-size = <0x800000>;
			i-cache-size = <0x800000>;
		};

		l3-cache@30000870 {
			phandle = <0x65>;
			device_type = "cache";
			reg = <0x30000870>;
			status = "okay";
			cache-unified;
			d-cache-sets = <0x8>;
			i-cache-sets = <0x8>;
			d-cache-size = <0x800000>;
			i-cache-size = <0x800000>;
		};

		l3-cache@300008a0 {
			phandle = <0x69>;
			device_type = "cache";
			reg = <0x300008a0>;
			status = "okay";
			cache-unified;
			d-cache-sets = <0x8>;
			i-cache-sets = <0x8>;
			d-cache-size = <0x800000>;
			i-cache-size = <0x800000>;
		};

		l3-cache@300008a8 {
			phandle = <0x6d>;
			device_type = "cache";
			reg = <0x300008a8>;
			status = "okay";
			cache-unified;
			d-cache-sets = <0x8>;
			i-cache-sets = <0x8>;
			d-cache-size = <0x800000>;
			i-cache-size = <0x800000>;
		};

		l3-cache@300008b0 {
			phandle = <0x71>;
			device_type = "cache";
			reg = <0x300008b0>;
			status = "okay";
			cache-unified;
			d-cache-sets = <0x8>;
			i-cache-sets = <0x8>;
			d-cache-size = <0x800000>;
			i-cache-size = <0x800000>;
		};

		l3-cache@300008e8 {
			phandle = <0x75>;
			device_type = "cache";
			reg = <0x300008e8>;
			status = "okay";
			cache-unified;
			d-cache-sets = <0x8>;
			i-cache-sets = <0x8>;
			d-cache-size = <0x800000>;
			i-cache-size = <0x800000>;
		};

		l3-cache@300008f0 {
			phandle = <0x79>;
			device_type = "cache";
			reg = <0x300008f0>;
			status = "okay";
			cache-unified;
			d-cache-sets = <0x8>;
			i-cache-sets = <0x8>;
			d-cache-size = <0x800000>;
			i-cache-size = <0x800000>;
		};
	};

	fsps {
		phandle = <0x8b>;
		#address-cells = <0x1>;
		#size-cells = <0x0>;

		fsp@0 {
			phandle = <0x8c>;
			reg = <0x0>;
			compatible = "ibm,fsp", "ibm,fsp2";
			reg-offset = <0xb0011000>;
			hw-version = <0x2>;
			sw-version = <0x1>;
			primary;
			ibm,psi-links = <0x0 0x10>;
		};
	};

	ibm,opal {
		phandle = <0x28>;

		leds {
			phandle = <0x29>;
			led-mode = "lightpath";

			U8247.22L.1010C8A {
				phandle = <0x9d>;
				led-types = "attention";
			};
		};
	};

	interrupt-controller@3ffff80020000 {
		phandle = <0x2e>;
		compatible = "ibm,ppc-xicp", "IBM,power8-icp";
		ibm,interrupt-server-ranges = <0x20 0x8>;
		interrupt-controller;
		reg = <0x3ffff 0x80020000 0x0 0x1000 0x3ffff 0x80021000 0x0 0x1000 0x3ffff 0x80022000 0x0 0x1000 0x3ffff 0x80023000 0x0 0x1000 0x3ffff 0x80024000 0x0 0x1000 0x3ffff 0x80025000 0x0 0x1000 0x3ffff 0x80026000 0x0 0x1000 0x3ffff 0x80027000 0x0 0x1000>;
		#address-cells = <0x0>;
		device_type = "PowerPC-External-Interrupt-Presentation";
	};

	interrupt-controller@3ffff80030000 {
		phandle = <0x32>;
		compatible = "ibm,ppc-xicp", "IBM,power8-icp";
		ibm,interrupt-server-ranges = <0x30 0x8>;
		interrupt-controller;
		reg = <0x3ffff 0x80030000 0x0 0x1000 0x3ffff 0x80031000 0x0 0x1000 0x3ffff 0x80032000 0x0 0x1000 0x3ffff 0x80033000 0x0 0x1000 0x3ffff 0x80034000 0x0 0x1000 0x3ffff 0x80035000 0x0 0x1000 0x3ffff 0x80036000 0x0 0x1000 0x3ffff 0x80037000 0x0 0x1000>;
		#address-cells = <0x0>;
		device_type = "PowerPC-External-Interrupt-Presentation";
	};

	interrupt-controller@3ffff80060000 {
		phandle = <0x36>;
		compatible = "ibm,ppc-xicp", "IBM,power8-icp";
		ibm,interrupt-server-ranges = <0x60 0x8>;
		interrupt-controller;
		reg = <0x3ffff 0x80060000 0x0 0x1000 0x3ffff 0x80061000 0x0 0x1000 0x3ffff 0x80062000 0x0 0x1000 0x3ffff 0x80063000 0x0 0x1000 0x3ffff 0x80064000 0x0 0x1000 0x3ffff 0x80065000 0x0 0x1000 0x3ffff 0x80066000 0x0 0x1000 0x3ffff 0x80067000 0x0 0x1000>;
		#address-cells = <0x0>;
		device_type = "PowerPC-External-Interrupt-Presentation";
	};

	interrupt-controller@3ffff80068000 {
		phandle = <0x3a>;
		compatible = "ibm,ppc-xicp", "IBM,power8-icp";
		ibm,interrupt-server-ranges = <0x68 0x8>;
		interrupt-controller;
		reg = <0x3ffff 0x80068000 0x0 0x1000 0x3ffff 0x80069000 0x0 0x1000 0x3ffff 0x8006a000 0x0 0x1000 0x3ffff 0x8006b000 0x0 0x1000 0x3ffff 0x8006c000 0x0 0x1000 0x3ffff 0x8006d000 0x0 0x1000 0x3ffff 0x8006e000 0x0 0x1000 0x3ffff 0x8006f000 0x0 0x1000>;
		#address-cells = <0x0>;
		device_type = "PowerPC-External-Interrupt-Presentation";
	};

	interrupt-controller@3ffff80070000 {
		phandle = <0x3e>;
		compatible = "ibm,ppc-xicp", "IBM,power8-icp";
		ibm,interrupt-server-ranges = <0x70 0x8>;
		interrupt-controller;
		reg = <0x3ffff 0x80070000 0x0 0x1000 0x3ffff 0x80071000 0x0 0x1000 0x3ffff 0x80072000 0x0 0x1000 0x3ffff 0x80073000 0x0 0x1000 0x3ffff 0x80074000 0x0 0x1000 0x3ffff 0x80075000 0x0 0x1000 0x3ffff 0x80076000 0x0 0x1000 0x3ffff 0x80077000 0x0 0x1000>;
		#address-cells = <0x0>;
		device_type = "PowerPC-External-Interrupt-Presentation";
	};

	interrupt-controller@3ffff80128000 {
		phandle = <0x42>;
		compatible = "ibm,ppc-xicp", "IBM,power8-icp";
		ibm,interrupt-server-ranges = <0xa8 0x8>;
		interrupt-controller;
		reg = <0x3ffff 0x80128000 0x0 0x1000 0x3ffff 0x80129000 0x0 0x1000 0x3ffff 0x8012a000 0x0 0x1000 0x3ffff 0x8012b000 0x0 0x1000 0x3ffff 0x8012c000 0x0 0x1000 0x3ffff 0x8012d000 0x0 0x1000 0x3ffff 0x8012e000 0x0 0x1000 0x3ffff 0x8012f000 0x0 0x1000>;
		#address-cells = <0x0>;
		device_type = "PowerPC-External-Interrupt-Presentation";
	};

	interrupt-controller@3ffff80130000 {
		phandle = <0x46>;
		compatible = "ibm,ppc-xicp", "IBM,power8-icp";
		ibm,interrupt-server-ranges = <0xb0 0x8>;
		interrupt-controller;
		reg = <0x3ffff 0x80130000 0x0 0x1000 0x3ffff 0x80131000 0x0 0x1000 0x3ffff 0x80132000 0x0 0x1000 0x3ffff 0x80133000 0x0 0x1000 0x3ffff 0x80134000 0x0 0x1000 0x3ffff 0x80135000 0x0 0x1000 0x3ffff 0x80136000 0x0 0x1000 0x3ffff 0x80137000 0x0 0x1000>;
		#address-cells = <0x0>;
		device_type = "PowerPC-External-Interrupt-Presentation";
	};

	interrupt-controller@3ffff80160000 {
		phandle = <0x4a>;
		compatible = "ibm,ppc-xicp", "IBM,power8-icp";
		ibm,interrupt-server-ranges = <0xe0 0x8>;
		interrupt-controller;
		reg = <0x3ffff 0x80160000 0x0 0x1000 0x3ffff 0x80161000 0x0 0x1000 0x3ffff 0x80162000 0x0 0x1000 0x3ffff 0x80163000 0x0 0x1000 0x3ffff 0x80164000 0x0 0x1000 0x3ffff 0x80165000 0x0 0x1000 0x3ffff 0x80166000 0x0 0x1000 0x3ffff 0x80167000 0x0 0x1000>;
		#address-cells = <0x0>;
		device_type = "PowerPC-External-Interrupt-Presentation";
	};

	interrupt-controller@3ffff80168000 {
		phandle = <0x4e>;
		compatible = "ibm,ppc-xicp", "IBM,power8-icp";
		ibm,interrupt-server-ranges = <0xe8 0x8>;
		interrupt-controller;
		reg = <0x3ffff 0x80168000 0x0 0x1000 0x3ffff 0x80169000 0x0 0x1000 0x3ffff 0x8016a000 0x0 0x1000 0x3ffff 0x8016b000 0x0 0x1000 0x3ffff 0x8016c000 0x0 0x1000 0x3ffff 0x8016d000 0x0 0x1000 0x3ffff 0x8016e000 0x0 0x1000 0x3ffff 0x8016f000 0x0 0x1000>;
		#address-cells = <0x0>;
		device_type = "PowerPC-External-Interrupt-Presentation";
	};

	interrupt-controller@3ffff80170000 {
		phandle = <0x52>;
		compatible = "ibm,ppc-xicp", "IBM,power8-icp";
		ibm,interrupt-server-ranges = <0xf0 0x8>;
		interrupt-controller;
		reg = <0x3ffff 0x80170000 0x0 0x1000 0x3ffff 0x80171000 0x0 0x1000 0x3ffff 0x80172000 0x0 0x1000 0x3ffff 0x80173000 0x0 0x1000 0x3ffff 0x80174000 0x0 0x1000 0x3ffff 0x80175000 0x0 0x1000 0x3ffff 0x80176000 0x0 0x1000 0x3ffff 0x80177000 0x0 0x1000>;
		#address-cells = <0x0>;
		device_type = "PowerPC-External-Interrupt-Presentation";
	};

	interrupt-controller@3ffff80828000 {
		phandle = <0x56>;
		compatible = "ibm,ppc-xicp", "IBM,power8-icp";
		ibm,interrupt-server-ranges = <0x828 0x8>;
		interrupt-controller;
		reg = <0x3ffff 0x80828000 0x0 0x1000 0x3ffff 0x80829000 0x0 0x1000 0x3ffff 0x8082a000 0x0 0x1000 0x3ffff 0x8082b000 0x0 0x1000 0x3ffff 0x8082c000 0x0 0x1000 0x3ffff 0x8082d000 0x0 0x1000 0x3ffff 0x8082e000 0x0 0x1000 0x3ffff 0x8082f000 0x0 0x1000>;
		#address-cells = <0x0>;
		device_type = "PowerPC-External-Interrupt-Presentation";
	};

	interrupt-controller@3ffff80830000 {
		phandle = <0x5a>;
		compatible = "ibm,ppc-xicp", "IBM,power8-icp";
		ibm,interrupt-server-ranges = <0x830 0x8>;
		interrupt-controller;
		reg = <0x3ffff 0x80830000 0x0 0x1000 0x3ffff 0x80831000 0x0 0x1000 0x3ffff 0x80832000 0x0 0x1000 0x3ffff 0x80833000 0x0 0x1000 0x3ffff 0x80834000 0x0 0x1000 0x3ffff 0x80835000 0x0 0x1000 0x3ffff 0x80836000 0x0 0x1000 0x3ffff 0x80837000 0x0 0x1000>;
		#address-cells = <0x0>;
		device_type = "PowerPC-External-Interrupt-Presentation";
	};

	interrupt-controller@3ffff80860000 {
		phandle = <0x5e>;
		compatible = "ibm,ppc-xicp", "IBM,power8-icp";
		ibm,interrupt-server-ranges = <0x860 0x8>;
		interrupt-controller;
		reg = <0x3ffff 0x80860000 0x0 0x1000 0x3ffff 0x80861000 0x0 0x1000 0x3ffff 0x80862000 0x0 0x1000 0x3ffff 0x80863000 0x0 0x1000 0x3ffff 0x80864000 0x0 0x1000 0x3ffff 0x80865000 0x0 0x1000 0x3ffff 0x80866000 0x0 0x1000 0x3ffff 0x80867000 0x0 0x1000>;
		#address-cells = <0x0>;
		device_type = "PowerPC-External-Interrupt-Presentation";
	};

	interrupt-controller@3ffff80868000 {
		phandle = <0x62>;
		compatible = "ibm,ppc-xicp", "IBM,power8-icp";
		ibm,interrupt-server-ranges = <0x868 0x8>;
		interrupt-controller;
		reg = <0x3ffff 0x80868000 0x0 0x1000 0x3ffff 0x80869000 0x0 0x1000 0x3ffff 0x8086a000 0x0 0x1000 0x3ffff 0x8086b000 0x0 0x1000 0x3ffff 0x8086c000 0x0 0x1000 0x3ffff 0x8086d000 0x0 0x1000 0x3ffff 0x8086e000 0x0 0x1000 0x3ffff 0x8086f000 0x0 0x1000>;
		#address-cells = <0x0>;
		device_type = "PowerPC-External-Interrupt-Presentation";
	};

	interrupt-controller@3ffff80870000 {
		phandle = <0x66>;
		compatible = "ibm,ppc-xicp", "IBM,power8-icp";
		ibm,interrupt-server-ranges = <0x870 0x8>;
		interrupt-controller;
		reg = <0x3ffff 0x80870000 0x0 0x1000 0x3ffff 0x80871000 0x0 0x1000 0x3ffff 0x80872000 0x0 0x1000 0x3ffff 0x80873000 0x0 0x1000 0x3ffff 0x80874000 0x0 0x1000 0x3ffff 0x80875000 0x0 0x1000 0x3ffff 0x80876000 0x0 0x1000 0x3ffff 0x80877000 0x0 0x1000>;
		#address-cells = <0x0>;
		device_type = "PowerPC-External-Interrupt-Presentation";
	};

	interrupt-controller@3ffff80920000 {
		phandle = <0x6a>;
		compatible = "ibm,ppc-xicp", "IBM,power8-icp";
		ibm,interrupt-server-ranges = <0x8a0 0x8>;
		interrupt-controller;
		reg = <0x3ffff 0x80920000 0x0 0x1000 0x3ffff 0x80921000 0x0 0x1000 0x3ffff 0x80922000 0x0 0x1000 0x3ffff 0x80923000 0x0 0x1000 0x3ffff 0x80924000 0x0 0x1000 0x3ffff 0x80925000 0x0 0x1000 0x3ffff 0x80926000 0x0 0x1000 0x3ffff 0x80927000 0x0 0x1000>;
		#address-cells = <0x0>;
		device_type = "PowerPC-External-Interrupt-Presentation";
	};

	interrupt-controller@3ffff80928000 {
		phandle = <0x6e>;
		compatible = "ibm,ppc-xicp", "IBM,power8-icp";
		ibm,interrupt-server-ranges = <0x8a8 0x8>;
		interrupt-controller;
		reg = <0x3ffff 0x80928000 0x0 0x1000 0x3ffff 0x80929000 0x0 0x1000 0x3ffff 0x8092a000 0x0 0x1000 0x3ffff 0x8092b000 0x0 0x1000 0x3ffff 0x8092c000 0x0 0x1000 0x3ffff 0x8092d000 0x0 0x1000 0x3ffff 0x8092e000 0x0 0x1000 0x3ffff 0x8092f000 0x0 0x1000>;
		#address-cells = <0x0>;
		device_type = "PowerPC-External-Interrupt-Presentation";
	};

	interrupt-controller@3ffff80930000 {
		phandle = <0x72>;
		compatible = "ibm,ppc-xicp", "IBM,power8-icp";
		ibm,interrupt-server-ranges = <0x8b0 0x8>;
		interrupt-controller;
		reg = <0x3ffff 0x80930000 0x0 0x1000 0x3ffff 0x80931000 0x0 0x1000 0x3ffff 0x80932000 0x0 0x1000 0x3ffff 0x80933000 0x0 0x1000 0x3ffff 0x80934000 0x0 0x1000 0x3ffff 0x80935000 0x0 0x1000 0x3ffff 0x80936000 0x0 0x1000 0x3ffff 0x80937000 0x0 0x1000>;
		#address-cells = <0x0>;
		device_type = "PowerPC-External-Interrupt-Presentation";
	};

	interrupt-controller@3ffff80968000 {
		phandle = <0x76>;
		compatible = "ibm,ppc-xicp", "IBM,power8-icp";
		ibm,interrupt-server-ranges = <0x8e8 0x8>;
		interrupt-controller;
		reg = <0x3ffff 0x80968000 0x0 0x1000 0x3ffff 0x80969000 0x0 0x1000 0x3ffff 0x8096a000 0x0 0x1000 0x3ffff 0x8096b000 0x0 0x1000 0x3ffff 0x8096c000 0x0 0x1000 0x3ffff 0x8096d000 0x0 0x1000 0x3ffff 0x8096e000 0x0 0x1000 0x3ffff 0x8096f000 0x0 0x1000>;
		#address-cells = <0x0>;
		device_type = "PowerPC-External-Interrupt-Presentation";
	};

	interrupt-controller@3ffff80970000 {
		phandle = <0x7a>;
		compatible = "ibm,ppc-xicp", "IBM,power8-icp";
		ibm,interrupt-server-ranges = <0x8f0 0x8>;
		interrupt-controller;
		reg = <0x3ffff 0x80970000 0x0 0x1000 0x3ffff 0x80971000 0x0 0x1000 0x3ffff 0x80972000 0x0 0x1000 0x3ffff 0x80973000 0x0 0x1000 0x3ffff 0x80974000 0x0 0x1000 0x3ffff 0x80975000 0x0 0x1000 0x3ffff 0x80976000 0x0 0x1000 0x3ffff 0x80977000 0x0 0x1000>;
		#address-cells = <0x0>;
		device_type = "PowerPC-External-Interrupt-Presentation";
	};

	ipl-params {
		phandle = <0x7b>;
		#address-cells = <0x0>;
		#size-cells = <0x0>;

		fsp-serial {
			phandle = <0x7e>;
			#address-cells = <0x1>;
			#size-cells = <0x0>;

			serial@2a00 {
				phandle = <0x7f>;
				reg = <0x2a00>;
				ibm,loc-code = "U78CB.001.WZS00AL-P1-C1-T1";
				compatible = "ibm,fsp-serial";
			};
		};

		ipl-params {
			phandle = <0x7d>;
			#address-cells = <0x0>;
			#size-cells = <0x0>;
			cec-ipl-side = "perm";
			fsp-ipl-side = "perm";
			os-ipl-mode = <0x0>;
			cec-major-type = "cold";
		};

		platform-dump {
			phandle = <0x80>;
		};

		sys-params {
			phandle = <0x7c>;
			#address-cells = <0x0>;
			#size-cells = <0x0>;
			abc-bus-freq-mhz = < 0x00 0x1900 >;
			ibm,sys-model = " 22L";
			wxyz-bus-freq-mhz = < 0x00 0xfa0 >;
		};
	};

	memory@0 {
		phandle = <0x89>;
		device_type = "memory";
		ibm,chip-id = <0x0>;
		reg = <0x0 0x0 0x10 0x0>;
	};

	memory@1000000000 {
		phandle = <0x8a>;
		device_type = "memory";
		ibm,chip-id = <0x10>;
		reg = <0x10 0x0 0x10 0x0>;
	};

	vpd {
		phandle = <0x2>;
		compatible = "ibm,opal-v3-vpd";
		#size-cells = <0x0>;
		#address-cells = <0x1>;
		ibm,vpd = <0x84b00052 0x54045653 0x59534452 0x6535953 0x54454d42 0x52025330 0x53450731 0x30313043 0x38415347 0x7202020 0x20202020 0x544d0838 0x3234372d 0x32324c54 0x4e082020 0x20202020 0x20204d4e 0x7202020 0x20202020 0x49440220 0x20535506 0x4ac1a 0x43544e4e 0x10202020 0x20202020 0x20202020 0x20202020 0x20524704 0xf0c00000 0x52420433 0x20202057 0x4e0c4330 0x35303736 0x30373830 0x44324656 0x20535638 0x31305f30 0x32390000 0x0 0x0 0x0 0x0 0x0 0x504603 0x78 0x0>;
		ibm,loc-code = "U8247.22L.1010C8A";

		root-node-vpd@a000 {
			phandle = <0x3>;
			ibm,loc-code = "U8247.22L.1010C8A";
			fru-type = [56 56];
			reg = <0xa000>;
			#size-cells = <0x0>;
			#address-cells = <0x1>;

			enclosure-fault-led@a300 {
				phandle = <0x7>;
				ibm,loc-code = "U78CB.001.WZS00AL";
				fru-type = [45 46];
				reg = <0xa300>;
				#size-cells = <0x0>;
				#address-cells = <0x1>;
			};

			enclosure-led@a200 {
				phandle = <0x6>;
				ibm,loc-code = "U78CB.001.WZS00AL";
				fru-type = [45 49];
				reg = <0xa200>;
				#size-cells = <0x0>;
				#address-cells = <0x1>;
			};

			enclosure@1e00 {
				phandle = <0x5>;
				ibm,loc-code = "U78CB.001.WZS00AL";
				fru-type = [45 56];
				reg = <0x1e00>;
				#size-cells = <0x0>;
				#address-cells = <0x1>;
				ibm,vpd = <0x848c0052 0x54045649 0x4e494452 0x10492f4f 0x20424143 0x4b504c41 0x4e452020 0x20434501 0x31565a02 0x3032464e 0x7303045 0x32303232 0x504e0730 0x30453339 0x3937534e 0xc594c31 0x30554634 0x324c3031 0x33434304 0x32434436 0x50520821 0x0 0x48 0x45043030 0x30324354 0x480f300 0x26485702 0x44233 0x6000000 0x142 0x34010042 0x370c0000 0x0 0x0 0x5046 0x2000078 0x841c0052 0x54044c58 0x5230565a 0x230314c 0x58083100 0x4010030 0x425046 0x2000078 0x84440052 0x54045643 0x454e4452 0x6434543 0x20202053 0x4507575a 0x53303041 0x4c544d08 0x20202020 0x20202020 0x46430837 0x3843422d 0x30303152 0x47040000 0x5242 0x4202020 0x20504603 0x78 0x0>;
				fru-number = "00E2022";
				serial-number = "YL10UF42L013";
				part-number = "00E3997";
				ccin-extension = [31 00];
				hw-version = [00];
				card-type = [80 f3 00];
				hw-characteristics = [00];
				ccin = "2CD6";
				description = "System planar 2S2U";

				air-mover@3a00 {
					phandle = <0xf>;
					ibm,loc-code = "U78CB.001.WZS00AL-A1";
					fru-type = [41 4d];
					reg = <0x3a00>;
					#size-cells = <0x0>;
					#address-cells = <0x1>;
				};

				air-mover@3a01 {
					phandle = <0x10>;
					ibm,loc-code = "U78CB.001.WZS00AL-A3";
					fru-type = [41 4d];
					reg = <0x3a01>;
					#size-cells = <0x0>;
					#address-cells = <0x1>;
				};

				air-mover@3a02 {
					phandle = <0x11>;
					ibm,loc-code = "U78CB.001.WZS00AL-A4";
					fru-type = [41 4d];
					reg = <0x3a02>;
					#size-cells = <0x0>;
					#address-cells = <0x1>;
				};

				air-mover@3a03 {
					phandle = <0x12>;
					ibm,loc-code = "U78CB.001.WZS00AL-A6";
					fru-type = [41 4d];
					reg = <0x3a03>;
					#size-cells = <0x0>;
					#address-cells = <0x1>;
				};

				air-mover@3a04 {
					phandle = <0x13>;
					ibm,loc-code = "U78CB.001.WZS00AL-A2";
					fru-type = [41 4d];
					reg = <0x3a04>;
					#size-cells = <0x0>;
					#address-cells = <0x1>;
				};

				air-mover@3a05 {
					phandle = <0x14>;
					ibm,loc-code = "U78CB.001.WZS00AL-A5";
					fru-type = [41 4d];
					reg = <0x3a05>;
					#size-cells = <0x0>;
					#address-cells = <0x1>;
				};

				backplane@800 {
					phandle = <0x8>;
					ibm,loc-code = "U78CB.001.WZS00AL-P1";
					fru-type = [42 50];
					reg = <0x800>;
					#size-cells = <0x0>;
					#address-cells = <0x1>;
					ibm,vpd = <0x848c0052 0x54045649 0x4e494452 0x10492f4f 0x20424143 0x4b504c41 0x4e452020 0x20434501 0x31565a02 0x3032464e 0x7303045 0x32303232 0x504e0730 0x30453339 0x3937534e 0xc594c31 0x30554634 0x324c3031 0x33434304 0x32434436 0x50520821 0x0 0x48 0x45043030 0x30324354 0x480f300 0x26485702 0x44233 0x6000000 0x142 0x34010042 0x370c0000 0x0 0x0 0x5046 0x2000078 0x841c0052 0x54044c58 0x5230565a 0x230314c 0x58083100 0x4010030 0x425046 0x2000078 0x0>;
					fru-number = "00E2022";
					serial-number = "YL10UF42L013";
					part-number = "00E3997";
					ccin-extension = [31 00];
					hw-version = [00];
					card-type = [80 f3 00];
					hw-characteristics = [00];
					ccin = "2CD6";
					description = "System planar 2S2U";

					anchor-card@500 {
						phandle = <0x1a>;
						ibm,loc-code = "U78CB.001.WZS00AL-P1-C13";
						fru-type = [41 56];
						reg = <0x500>;
						#size-cells = <0x0>;
						#address-cells = <0x1>;
						ibm,vpd = <0x84cc0052 0x54045649 0x4e494452 0x10414e43 0x484f5220 0x20202020 0x20202020 0x20434501 0x31565a02 0x3031464e 0x7303045 0x33343237 0x504e0730 0x30453231 0x3438534e 0xc594c31 0x30313134 0x32523030 0x30434304 0x35323444 0x50520881 0x300000 0x48 0x45043030 0x31304354 0x440b400 0x485702 0x14233 0x6000000 0x142 0x34010042 0x370c0000 0x0 0x0 0x4239 0x3c435340 0x55110351 0xdd6da253 0x5049652f 0x45748f7b 0x44d31c5 0x31833edf 0x1e75724d 0x328d48c1 0xb4246b02 0xee4d3367 0xb454d848 0x9f3a254d 0x340dadc4 0x4124b5ed 0xd5504603 0x78 0x0>;
						fru-number = "00E3427";
						serial-number = "YL101142R000";
						part-number = "00E2148";
						ccin-extension = [31 00];
						hw-version = [00];
						card-type = [40 b4 00];
						hw-characteristics = [00];
						ccin = "524D";
						description = "System Anchor Card - IBM Power 822L";
					};

					backplane-extender@900 {
						phandle = <0x15>;
						ibm,loc-code = "U78CB.001.WZS00AL-P1-C1";
						fru-type = [42 58];
						reg = <0x900>;
						#size-cells = <0x0>;
						#address-cells = <0x1>;
						ibm,vpd = <0x84800052 0x54045649 0x4e494452 0x104e4154 0x49564520 0x492f4f20 0x43415244 0x20434501 0x31565a02 0x3031464e 0x7303045 0x32313634 0x504e0730 0x30453338 0x3131534e 0xc594c31 0x30554634 0x324c3030 0x31434304 0x32423042 0x48450430 0x30303143 0x540480b5 0x4857 0x2000142 0x33060000 0x0 0x42340100 0x42370c00 0x0 0x0 0x50 0x46010078 0x0>;
						fru-number = "00E2164";
						serial-number = "YL10UF42L001";
						part-number = "00E3811";
						ccin-extension = [31 00];
						hw-version = [00];
						card-type = [80 b5 00];
						hw-characteristics = [00];
						ccin = "2B0B";
						description = "Native I/O Card";

						serial-connector@2a00 {
							phandle = <0x27>;
							ibm,loc-code = "U78CB.001.WZS00AL-P1-C1-T1";
							fru-type = [43 53];
							reg = <0x2a00>;
							#size-cells = <0x0>;
							#address-cells = <0x1>;
						};

						usb-connector@2901 {
							phandle = <0x25>;
							ibm,loc-code = "U78CB.001.WZS00AL-P1-C1-T2";
							fru-type = [43 55];
							reg = <0x2901>;
							#size-cells = <0x0>;
							#address-cells = <0x1>;
						};

						usb-connector@2904 {
							phandle = <0x26>;
							ibm,loc-code = "U78CB.001.WZS00AL-P1-C1-T3";
							fru-type = [43 55];
							reg = <0x2904>;
							#size-cells = <0x0>;
							#address-cells = <0x1>;
						};
					};

					ethernet-connector@2800 {
						phandle = <0x1b>;
						ibm,loc-code = "U78CB.001.WZS00AL-P1-T1 ";
						fru-type = [43 45];
						reg = <0x2800>;
						#size-cells = <0x0>;
						#address-cells = <0x1>;
					};

					ethernet-connector@2801 {
						phandle = <0x1c>;
						ibm,loc-code = "U78CB.001.WZS00AL-P1-T2 ";
						fru-type = [43 45];
						reg = <0x2801>;
						#size-cells = <0x0>;
						#address-cells = <0x1>;
					};

					ms-dimm@d000 {
						phandle = <0x21>;
						ibm,loc-code = "U78CB.001.WZS00AL-P1-C16";
						fru-type = [4d 53];
						reg = <0xd000>;
						#size-cells = <0x0>;
						#address-cells = <0x1>;
						ibm,vpd = <0x84940052 0x54045649 0x4e494452 0x1049424d 0x20333247 0x42204d53 0x20202020 0x20434501 0x31565a02 0x3132464e 0x730304a 0x41363634 0x504e0730 0x304a4136 0x3634534e 0xc594831 0x304d5534 0x32443141 0x39434304 0x33314539 0x50520849 0x0 0x1000053 0x5a073030 0x33323736 0x38484504 0x30303031 0x43540400 0x48 0x57020100 0x42330600 0x0 0x423401 0x42370c 0x0 0x0 0x0 0x50460078 0x0>;
						fru-number = "00JA664";
						serial-number = "YH10MU42D1A9";
						part-number = "00JA664";
						ccin-extension = [31 00];
						hw-version = [01 00];
						card-type = [00];
						hw-characteristics = [00];
						ccin = "31E9";
						description = "32GB CDIMM";
						ibm,chip-id = <0x0>;
						ibm,memory-bus-frequency = <0x0 0x0>;
						size = "32768";
					};

					ms-dimm@d002 {
						phandle = <0x22>;
						ibm,loc-code = "U78CB.001.WZS00AL-P1-C18";
						fru-type = [4d 53];
						reg = <0xd002>;
						#size-cells = <0x0>;
						#address-cells = <0x1>;
						ibm,vpd = <0x84940052 0x54045649 0x4e494452 0x1049424d 0x20333247 0x42204d53 0x20202020 0x20434501 0x31565a02 0x3132464e 0x730304a 0x41363634 0x504e0730 0x304a4136 0x3634534e 0xc594831 0x304d5534 0x32443141 0x36434304 0x33314539 0x50520849 0x0 0x1000053 0x5a073030 0x33323736 0x38484504 0x30303031 0x43540400 0x48 0x57020100 0x42330600 0x0 0x423401 0x42370c 0x0 0x0 0x0 0x50460078 0x0>;
						fru-number = "00JA664";
						serial-number = "YH10MU42D1A6";
						part-number = "00JA664";
						ccin-extension = [31 00];
						hw-version = [01 00];
						card-type = [00];
						hw-characteristics = [00];
						ccin = "31E9";
						description = "32GB CDIMM";
						ibm,chip-id = <0x0>;
						ibm,memory-bus-frequency = <0x0 0x0>;
						size = "32768";
					};

					ms-dimm@d008 {
						phandle = <0x23>;
						ibm,loc-code = "U78CB.001.WZS00AL-P1-C24";
						fru-type = [4d 53];
						reg = <0xd008>;
						#size-cells = <0x0>;
						#address-cells = <0x1>;
						ibm,vpd = <0x84940052 0x54045649 0x4e494452 0x1049424d 0x20333247 0x42204d53 0x20202020 0x20434501 0x31565a02 0x3132464e 0x730304a 0x41363634 0x504e0730 0x304a4136 0x3634534e 0xc594831 0x304d5534 0x32433137 0x54434304 0x33314539 0x50520849 0x0 0x1000053 0x5a073030 0x33323736 0x38484504 0x30303031 0x43540400 0x48 0x57020100 0x42330600 0x0 0x423401 0x42370c 0x0 0x0 0x0 0x50460078 0x0>;
						fru-number = "00JA664";
						serial-number = "YH10MU42C17T";
						part-number = "00JA664";
						ccin-extension = [31 00];
						hw-version = [01 00];
						card-type = [00];
						hw-characteristics = [00];
						ccin = "31E9";
						description = "32GB CDIMM";
						ibm,chip-id = <0x10>;
						ibm,memory-bus-frequency = <0x0 0x0>;
						size = "32768";
					};

					ms-dimm@d00a {
						phandle = <0x24>;
						ibm,loc-code = "U78CB.001.WZS00AL-P1-C26";
						fru-type = [4d 53];
						reg = <0xd00a>;
						#size-cells = <0x0>;
						#address-cells = <0x1>;
						ibm,vpd = <0x84940052 0x54045649 0x4e494452 0x1049424d 0x20333247 0x42204d53 0x20202020 0x20434501 0x31565a02 0x3132464e 0x730304a 0x41363634 0x504e0730 0x304a4136 0x3634534e 0xc594831 0x304d5534 0x32433141 0x48434304 0x33314539 0x50520849 0x0 0x1000053 0x5a073030 0x33323736 0x38484504 0x30303031 0x43540400 0x48 0x57020100 0x42330600 0x0 0x423401 0x42370c 0x0 0x0 0x0 0x50460078 0x0>;
						fru-number = "00JA664";
						serial-number = "YH10MU42C1AH";
						part-number = "00JA664";
						ccin-extension = [31 00];
						hw-version = [01 00];
						card-type = [00];
						hw-characteristics = [00];
						ccin = "31E9";
						description = "32GB CDIMM";
						ibm,chip-id = <0x10>;
						ibm,memory-bus-frequency = <0x0 0x0>;
						size = "32768";
					};

					processor@1000 {
						phandle = <0x16>;
						ibm,loc-code = "U78CB.001.WZS00AL-P1-C32";
						fru-type = [50 46];
						reg = <0x1000>;
						#size-cells = <0x0>;
						#address-cells = <0x1>;
						ibm,vpd = [84 8c 00 52 54 04 56 49 4e 49 44 52 10 31 30 2d 57 41 59 20 50 52 4f 43 20 43 55 4f 44 46 4e 07 30 30 46 58 35 31 38 50 4e 07 30 30 46 58 37 34 30 53 4e 0c 59 41 31 39 33 32 30 39 36 39 35 31 43 43 04 35 34 45 38 48 45 04 30 30 30 31 43 54 04 00 00 00 00 48 57 02 00 01 42 33 06 00 00 00 00 00 00 42 34 01 00 42 37 0c 00 00 00 00 00 00 00 00 00 00 00 00 50 52 08 35 00 50 01 22 00 80 01 56 5a 02 30 31 43 45 01 31 50 46 02 00 00 78 00];
						fru-number = "00FX518";
						serial-number = "YA1932096951";
						part-number = "00FX740";
						ccin-extension = [31 00];
						hw-version = [00];
						card-type = [00];
						hw-characteristics = [00];
						ccin = "54E8";
						description = "10-WAY PROC CUOD";
						ibm,chip-id = <0x0>;
					};

					processor@1001 {
						phandle = <0x17>;
						ibm,loc-code = "U78CB.001.WZS00AL-P1-C32";
						fru-type = [50 46];
						reg = <0x1001>;
						#size-cells = <0x0>;
						#address-cells = <0x1>;
						ibm,vpd = [84 8c 00 52 54 04 56 49 4e 49 44 52 10 31 30 2d 57 41 59 20 50 52 4f 43 20 43 55 4f 44 46 4e 07 30 30 46 58 35 31 38 50 4e 07 30 30 46 58 37 34 30 53 4e 0c 59 41 31 39 33 32 30 39 36 39 35 31 43 43 04 35 34 45 38 48 45 04 30 30 30 31 43 54 04 00 00 00 00 48 57 02 00 01 42 33 06 00 00 00 00 00 00 42 34 01 00 42 37 0c 00 00 00 00 00 00 00 00 00 00 00 00 50 52 08 35 00 50 01 22 00 80 01 56 5a 02 30 31 43 45 01 31 50 46 02 00 00 78 00];
						fru-number = "00FX518";
						serial-number = "YA1932096951";
						part-number = "00FX740";
						ccin-extension = [31 00];
						hw-version = [00];
						card-type = [00];
						hw-characteristics = [00];
						ccin = "54E8";
						description = "10-WAY PROC CUOD";
						ibm,chip-id = <0x1>;
					};

					processor@1002 {
						phandle = <0x18>;
						ibm,loc-code = "U78CB.001.WZS00AL-P1-C33";
						fru-type = [50 46];
						reg = <0x1002>;
						#size-cells = <0x0>;
						#address-cells = <0x1>;
						ibm,vpd = [84 8c 00 52 54 04 56 49 4e 49 44 52 10 31 30 2d 57 41 59 20 50 52 4f 43 20 43 55 4f 44 46 4e 07 30 30 46 58 35 31 38 50 4e 07 30 30 46 58 37 34 30 53 4e 0c 59 41 31 39 33 32 30 39 36 39 35 30 43 43 04 35 34 45 38 48 45 04 30 30 30 31 43 54 04 00 00 00 00 48 57 02 00 01 42 33 06 00 00 00 00 00 00 42 34 01 00 42 37 0c 00 00 00 00 00 00 00 00 00 00 00 00 50 52 08 35 00 50 01 22 00 80 01 56 5a 02 30 31 43 45 01 31 50 46 02 00 00 78 00];
						fru-number = "00FX518";
						serial-number = "YA1932096950";
						part-number = "00FX740";
						ccin-extension = [31 00];
						hw-version = [00];
						card-type = [00];
						hw-characteristics = [00];
						ccin = "54E8";
						description = "10-WAY PROC CUOD";
						ibm,chip-id = <0x10>;
					};

					processor@1003 {
						phandle = <0x19>;
						ibm,loc-code = "U78CB.001.WZS00AL-P1-C33";
						fru-type = [50 46];
						reg = <0x1003>;
						#size-cells = <0x0>;
						#address-cells = <0x1>;
						ibm,vpd = [84 8c 00 52 54 04 56 49 4e 49 44 52 10 31 30 2d 57 41 59 20 50 52 4f 43 20 43 55 4f 44 46 4e 07 30 30 46 58 35 31 38 50 4e 07 30 30 46 58 37 34 30 53 4e 0c 59 41 31 39 33 32 30 39 36 39 35 30 43 43 04 35 34 45 38 48 45 04 30 30 30 31 43 54 04 00 00 00 00 48 57 02 00 01 42 33 06 00 00 00 00 00 00 42 34 01 00 42 37 0c 00 00 00 00 00 00 00 00 00 00 00 00 50 52 08 35 00 50 01 22 00 80 01 56 5a 02 30 31 43 45 01 31 50 46 02 00 00 78 00];
						fru-number = "00FX518";
						serial-number = "YA1932096950";
						part-number = "00FX740";
						ccin-extension = [31 00];
						hw-version = [00];
						card-type = [00];
						hw-characteristics = [00];
						ccin = "54E8";
						description = "10-WAY PROC CUOD";
						ibm,chip-id = <0x11>;
					};

					usb-connector@2900 {
						phandle = <0x1d>;
						ibm,loc-code = "U78CB.001.WZS00AL-P1-T5";
						fru-type = [43 55];
						reg = <0x2900>;
						#size-cells = <0x0>;
						#address-cells = <0x1>;
					};

					usb-connector@2902 {
						phandle = <0x1e>;
						ibm,loc-code = "U78CB.001.WZS00AL-P1-T6";
						fru-type = [43 55];
						reg = <0x2902>;
						#size-cells = <0x0>;
						#address-cells = <0x1>;
					};

					usb-connector@2903 {
						phandle = <0x1f>;
						ibm,loc-code = "U78CB.001.WZS00AL-P1-T3";
						fru-type = [43 55];
						reg = <0x2903>;
						#size-cells = <0x0>;
						#address-cells = <0x1>;
					};

					usb-connector@2905 {
						phandle = <0x20>;
						ibm,loc-code = "U78CB.001.WZS00AL-P1-T4";
						fru-type = [43 55];
						reg = <0x2905>;
						#size-cells = <0x0>;
						#address-cells = <0x1>;
					};
				};

				dasd-backplane@2400 {
					phandle = <0xb>;
					ibm,loc-code = "U78CB.001.WZS00AL-P2";
					fru-type = [44 42];
					reg = <0x2400>;
					#size-cells = <0x0>;
					#address-cells = <0x1>;
				};

				dasd-backplane@2401 {
					phandle = <0xc>;
					ibm,loc-code = "U78CB.001.WZS00AL-P2";
					fru-type = [44 42];
					reg = <0x2401>;
					#size-cells = <0x0>;
					#address-cells = <0x1>;
				};

				op-panel@300 {
					phandle = <0xa>;
					ibm,loc-code = "U78CB.001.WZS00AL-D1";
					fru-type = [4f 50];
					reg = <0x300>;
					#size-cells = <0x0>;
					#address-cells = <0x1>;
					ibm,vpd = <0x84800052 0x54045649 0x4e494452 0x10434543 0x204f5020 0x50414e45 0x4c202020 0x20434501 0x31565a02 0x3032464e 0x7303045 0x31393636 0x504e0730 0x30453337 0x3730534e 0xc594c31 0x30554634 0x31383030 0x46434304 0x32423038 0x48450430 0x30303143 0x540480b5 0x4857 0x2000342 0x33060000 0x0 0x42340100 0x42370c00 0x0 0x0 0x50 0x46010078 0x0>;
					fru-number = "00E1966";
					serial-number = "YL10UF41800F";
					part-number = "00E3770";
					ccin-extension = [31 00];
					hw-version = [00];
					card-type = [80 b5 00];
					hw-characteristics = [00];
					ccin = "2B08";
					description = "CEC OP PANEL";
				};

				power-supply@3100 {
					phandle = <0xd>;
					ibm,loc-code = "U78CB.001.WZS00AL-E1";
					fru-type = [50 53];
					reg = <0x3100>;
					#size-cells = <0x0>;
					#address-cells = <0x1>;
				};

				power-supply@3101 {
					phandle = <0xe>;
					ibm,loc-code = "U78CB.001.WZS00AL-E2";
					fru-type = [50 53];
					reg = <0x3101>;
					#size-cells = <0x0>;
					#address-cells = <0x1>;
				};

				service-processor@200 {
					phandle = <0x9>;
					ibm,loc-code = "U78CB.001.WZS00AL-P1";
					fru-type = [53 50];
					reg = <0x200>;
					#size-cells = <0x0>;
					#address-cells = <0x1>;
					ibm,vpd = <0x848c0052 0x54045649 0x4e494452 0x10492f4f 0x20424143 0x4b504c41 0x4e452020 0x20434501 0x31565a02 0x3032464e 0x7303045 0x32303232 0x504e0730 0x30453339 0x3937534e 0xc594c31 0x30554634 0x324c3031 0x33434304 0x32434436 0x50520821 0x0 0x48 0x45043030 0x30324354 0x480f300 0x26485702 0x44233 0x6000000 0x142 0x34010042 0x370c0000 0x0 0x0 0x5046 0x2000078 0x841c0052 0x54044c58 0x5230565a 0x230314c 0x58083100 0x4010030 0x425046 0x2000078 0x84500052 0x54045652 0x31304452 0x10465350 0x20202020 0x20202020 0x20202020 0x20464704 0x564e5350 0x44430f42 0x44203230 0x31323038 0x32333038 0x3030464c 0x14503120 0x20202020 0x20202020 0x20202020 0x20202020 0x20504603 0x78 0x84400052 0x54045657 0x31304452 0x10465350 0x20565731 0x30202020 0x20202020 0x20474420 0x0 0x0 0x0 0x0 0x0 0x0 0x0 0x0 0x50460078 0x0>;
					fru-number = "00E2022";
					serial-number = "YL10UF42L013";
					part-number = "00E3997";
					ccin-extension = [31 00];
					hw-version = [00];
					card-type = [80 f3 00];
					hw-characteristics = [00];
					ccin = "2CD6";
					description = "System planar 2S2U";
				};
			};

			system-vpd@1c00 {
				phandle = <0x4>;
				ibm,loc-code = "U8247.22L.1010C8A";
				fru-type = [53 56];
				reg = <0x1c00>;
				#size-cells = <0x0>;
				#address-cells = <0x1>;
			};
		};
	};

	xscom@3fc0000000000 {
		phandle = <0x81>;
		ibm,chip-id = <0x0>;
		ibm,proc-chip-id = <0x0>;
		#address-cells = <0x1>;
		#size-cells = <0x1>;
		scom-controller;
		compatible = "ibm,xscom", "ibm,power8-xscom";
		reg = <0x3fc00 0x0 0x8 0x0>;
		bus-frequency = <0x0 0x1dcd6500>;
		ibm,dbob-id = <0x0>;
		ibm,occ-functional-state = <0x1>;
		ibm,loc-code = "U78CB.001.WZS00AL-P1-C32";
		ibm,module-vpd = <0xcafebeef 0x10000 0x3e067c18>;
		part-number = "00KV627";
		serial-number = "YA1932096951";
		ibm,ccm-node-id = <0x0>;
		ibm,hw-card-id = <0x0>;
		ibm,hw-module-id = <0x0>;
		ibm,mem-interleave-scope = <0x0>;

		chiptod@40000 {
			phandle = <0x8d>;
			reg = <0x40000 0x34>;
			compatible = "ibm,power-chiptod", "ibm,power8-chiptod";
			primary;
		};

		nx@2010000 {
			phandle = <0x91>;
			compatible = "ibm,power-nx", "ibm,power8-nx";
			reg = <0x2010000 0x4000>;
		};

		pbcq@2012000 {
			phandle = <0x95>;
			reg = <0x2012000 0x20 0x9012000 0x05 0x9013c00 0x15>;
			compatible = "ibm,power8-pbcq";
			ibm,phb-index = <0x0>;
			ibm,hub-id = <0x0>;
			ibm,loc-code = "U78CB.001.WZS00AL-P1-C32";
			ibm,use-ab-detect;
			ibm,lane-eq = <0x77777777 0x77777777 0x77777777 0x77777777 0x77777777 0x77777777 0x77777777 0x77777777>;
		};

		pbcq@2012400 {
			phandle = <0x96>;
			reg = <0x2012400 0x20 0x9012400 0x05 0x9013c40 0x15>;
			compatible = "ibm,power8-pbcq";
			ibm,phb-index = <0x1>;
			ibm,hub-id = <0x0>;
			ibm,loc-code = "U78CB.001.WZS00AL-P1-C32";
			ibm,use-ab-detect;
			ibm,lane-eq = <0x77777777 0x77777777 0x77777777 0x77777777 0x0 0x0 0x0 0x0>;
		};

		psihb@2010900 {
			phandle = <0x82>;
			reg = <0x2010900 0x20>;
			compatible = "ibm,power8-psihb-x", "ibm,psihb-x";
			boot-link;
			status = "ok";
		};
	};

	xscom@3fc0800000000 {
		phandle = <0x83>;
		ibm,chip-id = <0x1>;
		ibm,proc-chip-id = <0x1>;
		#address-cells = <0x1>;
		#size-cells = <0x1>;
		scom-controller;
		compatible = "ibm,xscom", "ibm,power8-xscom";
		reg = <0x3fc08 0x0 0x8 0x0>;
		bus-frequency = <0x0 0x1dcd6500>;
		ibm,dbob-id = <0x0>;
		ibm,occ-functional-state = <0x1>;
		ibm,loc-code = "U78CB.001.WZS00AL-P1-C32";
		ibm,module-vpd = <0xcafebeef 0x10000 0x1b85218f>;
		part-number = "00KV627";
		serial-number = "YA1932096951";
		ibm,ccm-node-id = <0x0>;
		ibm,hw-card-id = <0x0>;
		ibm,hw-module-id = <0x0>;
		ibm,mem-interleave-scope = <0x0>;

		chiptod@40000 {
			phandle = <0x8e>;
			reg = <0x40000 0x34>;
			compatible = "ibm,power-chiptod", "ibm,power8-chiptod";
		};

		nx@2010000 {
			phandle = <0x92>;
			compatible = "ibm,power-nx", "ibm,power8-nx";
			reg = <0x2010000 0x4000>;
		};

		pbcq@2012000 {
			phandle = <0x97>;
			reg = <0x2012000 0x20 0x9012000 0x05 0x9013c00 0x15>;
			compatible = "ibm,power8-pbcq";
			ibm,phb-index = <0x0>;
			ibm,hub-id = <0x1>;
			ibm,loc-code = "U78CB.001.WZS00AL-P1-C32";
			ibm,use-ab-detect;
			ibm,lane-eq = <0x77777777 0x77777777 0x77777777 0x77777777 0x77777777 0x77777777 0x77777777 0x77777777>;
		};

		pbcq@2012400 {
			phandle = <0x98>;
			reg = <0x2012400 0x20 0x9012400 0x05 0x9013c40 0x15>;
			compatible = "ibm,power8-pbcq";
			ibm,phb-index = <0x1>;
			ibm,hub-id = <0x1>;
			ibm,loc-code = "U78CB.001.WZS00AL-P1-C32";
			ibm,use-ab-detect;
			ibm,lane-eq = <0x68686868 0x68686868 0x68686868 0x68686868 0x0 0x0 0x0 0x0>;
		};

		psihb@2010900 {
			phandle = <0x84>;
			reg = <0x2010900 0x20>;
			compatible = "ibm,power8-psihb-x", "ibm,psihb-x";
		};
	};

	xscom@3fc8000000000 {
		phandle = <0x85>;
		ibm,chip-id = <0x10>;
		ibm,proc-chip-id = <0x2>;
		#address-cells = <0x1>;
		#size-cells = <0x1>;
		scom-controller;
		compatible = "ibm,xscom", "ibm,power8-xscom";
		reg = <0x3fc80 0x0 0x8 0x0>;
		bus-frequency = <0x0 0x1dcd6500>;
		ibm,dbob-id = <0x0>;
		ibm,occ-functional-state = <0x1>;
		ibm,loc-code = "U78CB.001.WZS00AL-P1-C33";
		ibm,module-vpd = <0xcafebeef 0x10000 0x36f99ead>;
		part-number = "00KV627";
		serial-number = "YA1932096950";
		ibm,ccm-node-id = <0x0>;
		ibm,hw-card-id = <0x0>;
		ibm,hw-module-id = <0x1>;
		ibm,mem-interleave-scope = <0x0>;

		chiptod@40000 {
			phandle = <0x8f>;
			reg = <0x40000 0x34>;
			compatible = "ibm,power-chiptod", "ibm,power8-chiptod";
			secondary;
		};

		nx@2010000 {
			phandle = <0x93>;
			compatible = "ibm,power-nx", "ibm,power8-nx";
			reg = <0x2010000 0x4000>;
		};

		pbcq@2012000 {
			phandle = <0x99>;
			reg = <0x2012000 0x20 0x9012000 0x05 0x9013c00 0x15>;
			compatible = "ibm,power8-pbcq";
			ibm,phb-index = <0x0>;
			ibm,hub-id = <0x2>;
			ibm,loc-code = "U78CB.001.WZS00AL-P1-C33";
			ibm,use-ab-detect;
			ibm,lane-eq = <0x77777777 0x77777777 0x77777777 0x77777777 0x77777777 0x77777777 0x77777777 0x77777777>;
		};

		psihb@2010900 {
			phandle = <0x86>;
			reg = <0x2010900 0x20>;
			compatible = "ibm,power8-psihb-x", "ibm,psihb-x";
			status = "ok";
		};
	};

	xscom@3fc8800000000 {
		phandle = <0x87>;
		ibm,chip-id = <0x11>;
		ibm,proc-chip-id = <0x3>;
		#address-cells = <0x1>;
		#size-cells = <0x1>;
		scom-controller;
		compatible = "ibm,xscom", "ibm,power8-xscom";
		reg = <0x3fc88 0x0 0x8 0x0>;
		bus-frequency = <0x0 0x1dcd6500>;
		ibm,dbob-id = <0x0>;
		ibm,occ-functional-state = <0x1>;
		ibm,loc-code = "U78CB.001.WZS00AL-P1-C33";
		ibm,module-vpd = <0xcafebeef 0x10000 0x65fe8f66>;
		part-number = "00KV627";
		serial-number = "YA1932096950";
		ibm,ccm-node-id = <0x0>;
		ibm,hw-card-id = <0x0>;
		ibm,hw-module-id = <0x1>;
		ibm,mem-interleave-scope = <0x0>;

		chiptod@40000 {
			phandle = <0x90>;
			reg = <0x40000 0x34>;
			compatible = "ibm,power-chiptod", "ibm,power8-chiptod";
		};

		nx@2010000 {
			phandle = <0x94>;
			compatible = "ibm,power-nx", "ibm,power8-nx";
			reg = <0x2010000 0x4000>;
		};

		pbcq@2012000 {
			phandle = <0x9a>;
			reg = <0x2012000 0x20 0x9012000 0x05 0x9013c00 0x15>;
			compatible = "ibm,power8-pbcq";
			ibm,phb-index = <0x0>;
			ibm,hub-id = <0x3>;
			ibm,loc-code = "U78CB.001.WZS00AL-P1-C33";
			ibm,use-ab-detect;
			ibm,lane-eq = <0x77777777 0x77777777 0x77777777 0x77777777 0x77777777 0x77777777 0x77777777 0x77777777>;
		};

		pbcq@2012400 {
			phandle = <0x9b>;
			reg = <0x2012400 0x20 0x9012400 0x05 0x9013c40 0x15>;
			compatible = "ibm,power8-pbcq";
			ibm,phb-index = <0x1>;
			ibm,hub-id = <0x3>;
			ibm,loc-code = "U78CB.001.WZS00AL-P1-C33";
			ibm,use-ab-detect;
			ibm,lane-eq = <0x77777777 0x77777777 0x77777777 0x77777777 0x0 0x0 0x0 0x0>;
		};

		psihb@2010900 {
			phandle = <0x88>;
			reg = <0x2010900 0x20>;
			compatible = "ibm,power8-psihb-x", "ibm,psihb-x";
		};
	};
};
